VERSION ""

NS_ :

BS_:

BU_: ENERGY_METER INERTIAL_MEASUREMENT_UNIT SENSOR_CONTROL_UNIT VEHICLE_CONTROL_UNIT ACCUMULATOR_CONTROL_UNIT MOTOR_CONTROLLER EMUS_BMS U2C

BO_ 150 CAR_ERROR_STATE: 8 Vector__XXX
 SG_ error_state_multiplexor M : 0|8@1+ (1,0) [0|0] "" Vector__XXX
 SG_ car_error_2 m0 : 9|1@1+ (1,0) [0|0] "" Vector__XXX
 SG_ car_error_1 m0 : 8|1@1+ (1,0) [0|0] "" Vector__XXX

BO_ 782 Team_Data_2_Message: 8 Vector__XXX
 SG_ Team_Signal_4 : 39|32@0- (1,0) [-2147483648|2147483647] ""  ENERGY_METER
 SG_ Team_Signal_3 : 7|32@0- (1,0) [-2147483648|2147483647] ""  ENERGY_METER

BO_ 781 Team_Data_1_Message: 8 Vector__XXX
 SG_ Team_Signal_2 : 39|32@0- (1,0) [-2147483648|2147483647] ""  ENERGY_METER
 SG_ Team_Signal_1 : 7|32@0- (1,0) [-2147483648|2147483647] ""  ENERGY_METER

BO_ 2147486373 INV_Diag_Buffer: 8 MOTOR_CONTROLLER
 SG_ INV_Diag_Data_3 : 48|16@1- (1,0) [-32768|32767] "" Vector__XXX
 SG_ INV_Diag_Data_2 : 32|16@1- (1,0) [-32768|32767] "" Vector__XXX
 SG_ INV_Diag_Data_1 : 16|16@1- (1,0) [-32768|32767] "" Vector__XXX
 SG_ INV_Buffer_Segment : 8|8@1+ (1,0) [0|5] "" Vector__XXX
 SG_ INV_Buffer_Record : 0|8@1+ (1,0) [0|255] "" Vector__XXX

BO_ 613 BRAKE_TEMPS: 8 SENSOR_CONTROL_UNIT
 SG_ BackRightBrakeTemp : 48|16@1- (0.01,0) [-327.68|327.67] "degC" Vector__XXX
 SG_ BackLeftBrakeTemp : 32|16@1- (0.01,0) [-327.68|327.67] "degC" Vector__XXX
 SG_ FrontRightBrakeTemp : 16|16@1- (0.01,0) [-327.68|327.67] "degC" Vector__XXX
 SG_ FrontLeftBrakeTemp : 0|16@1- (0.01,0) [-327.68|327.67] "degC" Vector__XXX

BO_ 599 TWO_FOOT_RULE: 8 SENSOR_CONTROL_UNIT
 SG_ HTL_CH_ID_TWO_FOOT_RULE : 0|8@1+ (1,0) [0|1] "" Vector__XXX

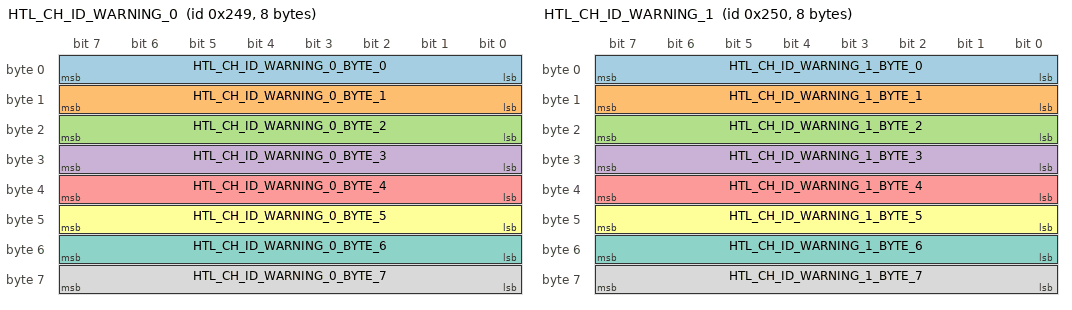
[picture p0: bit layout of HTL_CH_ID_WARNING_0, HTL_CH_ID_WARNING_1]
BO_ 585 HTL_CH_ID_WARNING_0: 8 SENSOR_CONTROL_UNIT
 SG_ HTL_CH_ID_WARNING_0_BYTE_0 : 0|8@1+ (1,0) [0|255] "" Vector__XXX
 SG_ HTL_CH_ID_WARNING_0_BYTE_1 : 8|8@1+ (1,0) [0|255] "" Vector__XXX
 SG_ HTL_CH_ID_WARNING_0_BYTE_2 : 16|8@1+ (1,0) [0|255] "" Vector__XXX
 SG_ HTL_CH_ID_WARNING_0_BYTE_3 : 24|8@1+ (1,0) [0|255] "" Vector__XXX
 SG_ HTL_CH_ID_WARNING_0_BYTE_4 : 32|8@1+ (1,0) [0|255] "" Vector__XXX
 SG_ HTL_CH_ID_WARNING_0_BYTE_5 : 40|8@1+ (1,0) [0|255] "" Vector__XXX
 SG_ HTL_CH_ID_WARNING_0_BYTE_6 : 48|8@1+ (1,0) [0|255] "" Vector__XXX
 SG_ HTL_CH_ID_WARNING_0_BYTE_7 : 56|8@1+ (1,0) [0|255] "" Vector__XXX

BO_ 592 HTL_CH_ID_WARNING_1: 8 SENSOR_CONTROL_UNIT
 SG_ HTL_CH_ID_WARNING_1_BYTE_0 : 0|8@1+ (1,0) [0|255] "" Vector__XXX
 SG_ HTL_CH_ID_WARNING_1_BYTE_1 : 8|8@1+ (1,0) [0|255] "" Vector__XXX
 SG_ HTL_CH_ID_WARNING_1_BYTE_2 : 16|8@1+ (1,0) [0|255] "" Vector__XXX
 SG_ HTL_CH_ID_WARNING_1_BYTE_3 : 24|8@1+ (1,0) [0|255] "" Vector__XXX
 SG_ HTL_CH_ID_WARNING_1_BYTE_4 : 32|8@1+ (1,0) [0|255] "" Vector__XXX
 SG_ HTL_CH_ID_WARNING_1_BYTE_5 : 40|8@1+ (1,0) [0|255] "" Vector__XXX
 SG_ HTL_CH_ID_WARNING_1_BYTE_6 : 48|8@1+ (1,0) [0|255] "" Vector__XXX
 SG_ HTL_CH_ID_WARNING_1_BYTE_7 : 56|8@1+ (1,0) [0|255] "" Vector__XXX

BO_ 544 HTL_CH_ID_APPS_TO_TORQUE_REQUEST: 8 SENSOR_CONTROL_UNIT
 SG_ HTL_CH_ID_APPS_TO_TORQUE_REQUEST : 0|16@1+ (0.1,0) [0|2400] "Nm" Vector__XXX

BO_ 537 HTL_CH_ID_BRAKE_PRESSED: 8 SENSOR_CONTROL_UNIT
 SG_ HTL_CH_ID_BRAKE_PRESSED : 0|8@1+ (1,0) [0|1] "" Vector__XXX

BO_ 536 HTL_CH_ID_APPS_PRESSED: 8 SENSOR_CONTROL_UNIT
 SG_ HTL_CH_ID_APPS_PRESSED : 0|8@1+ (1,0) [0|1] "" Vector__XXX

BO_ 535 HTL_CH_ID_SAFETY_LOOP_STATUS: 8 SENSOR_CONTROL_UNIT
 SG_ HTL_CH_ID_SAFETY_LOOP_STATUS : 0|8@1+ (1,0) [0|1] "" Vector__XXX

BO_ 1549 CAN_ENERGY_METER_TEMPERATURE: 8 ENERGY_METER
 SG_ Temp_31 m6 : 39|8@0+ (0.5,0) [0|127.5] "degC" Vector__XXX
 SG_ Temp_30 m6 : 31|8@0+ (0.5,0) [0|127.5] "degC" Vector__XXX
 SG_ Temp_29 m5 : 63|8@0+ (0.5,0) [0|127.5] "degC" Vector__XXX
 SG_ Temp_28 m5 : 55|8@0+ (0.5,0) [0|127.5] "degC" Vector__XXX
 SG_ Temp_27 m5 : 47|8@0+ (0.5,0) [0|127.5] "degC" Vector__XXX
 SG_ Temp_26 m5 : 39|8@0+ (0.5,0) [0|127.5] "degC" Vector__XXX
 SG_ Temp_25 m5 : 31|8@0+ (0.5,0) [0|127.5] "degC" Vector__XXX
 SG_ Temp_24 m4 : 63|8@0+ (0.5,0) [0|127.5] "degC" Vector__XXX
 SG_ Temp_23 m4 : 55|8@0+ (0.5,0) [0|127.5] "degC" Vector__XXX
 SG_ Temp_22 m4 : 47|8@0+ (0.5,0) [0|127.5] "degC" Vector__XXX
 SG_ Temp_21 m4 : 39|8@0+ (0.5,0) [0|127.5] "degC" Vector__XXX
 SG_ Temp_20 m4 : 31|8@0+ (0.5,0) [0|127.5] "degC" Vector__XXX
 SG_ Temp_19 m3 : 63|8@0+ (0.5,0) [0|127.5] "degC" Vector__XXX
 SG_ Temp_18 m3 : 55|8@0+ (0.5,0) [0|127.5] "degC" Vector__XXX
 SG_ Temp_17 m3 : 47|8@0+ (0.5,0) [0|127.5] "degC" Vector__XXX
 SG_ Temp_16 m3 : 39|8@0+ (0.5,0) [0|127.5] "degC" Vector__XXX
 SG_ Temp_15 m3 : 31|8@0+ (0.5,0) [0|127.5] "degC" Vector__XXX
 SG_ Temp_14 m2 : 63|8@0+ (0.5,0) [0|127.5] "degC" Vector__XXX
 SG_ Temp_13 m2 : 55|8@0+ (0.5,0) [0|127.5] "degC" Vector__XXX
 SG_ Temp_12 m2 : 47|8@0+ (0.5,0) [0|127.5] "degC" Vector__XXX
 SG_ Temp_11 m2 : 39|8@0+ (0.5,0) [0|127.5] "degC" Vector__XXX
 SG_ Temp_10 m2 : 31|8@0+ (0.5,0) [0|127.5] "degC" Vector__XXX
 SG_ Temp_9 m1 : 63|8@0+ (0.5,0) [0|127.5] "degC" Vector__XXX
 SG_ Temp_8 m1 : 55|8@0+ (0.5,0) [0|127.5] "degC" Vector__XXX
 SG_ Temp_7 m1 : 47|8@0+ (0.5,0) [0|127.5] "degC" Vector__XXX
 SG_ Temp_6 m1 : 39|8@0+ (0.5,0) [0|127.5] "degC" Vector__XXX
 SG_ Temp_5 m1 : 31|8@0+ (0.5,0) [0|127.5] "degC" Vector__XXX
 SG_ Temp_4 m0 : 63|8@0+ (0.5,0) [0|127.5] "degC" Vector__XXX
 SG_ Temp_3 m0 : 55|8@0+ (0.5,0) [0|127.5] "degC" Vector__XXX
 SG_ Temp_2 m0 : 47|8@0+ (0.5,0) [0|127.5] "degC" Vector__XXX
 SG_ Temp_1 m0 : 39|8@0+ (0.5,0) [0|127.5] "degC" Vector__XXX
 SG_ Temp_0 m0 : 31|8@0+ (0.5,0) [0|127.5] "degC" Vector__XXX
 SG_ Max_Temp : 23|8@0+ (0.5,0) [0|127.5] "degC" Vector__XXX
 SG_ Min_Temp : 15|8@0+ (0.5,0) [0|127.5] "degC" Vector__XXX
 SG_ Num_Sensors : 4|5@0+ (1,0) [0|31] "" Vector__XXX
 SG_ Temp_Multiplexor M : 7|3@0+ (1,0) [0|7] "" Vector__XXX

BO_ 1037 CAN_ENERGY_METER_STATUS: 5 ENERGY_METER
 SG_ EnergyMeterEnergy : 15|32@0- (1,0) [-3.4E+38|3.4E+38] "Whr" Vector__XXX
 SG_ EnergyMeterLogging : 1|1@0+ (1,0) [0|1] "" Vector__XXX
 SG_ EnergyMeterViolation : 0|1@0+ (1,0) [0|1] "" Vector__XXX

BO_ 269 CAN_ENERGY_METER_MEASUREMENT_MSG: 8 ENERGY_METER
 SG_ EnergyMeterVoltage : 39|32@0- (1,0) [-3.4E+38|3.4E+38] "V" Vector__XXX
 SG_ EnergyMeterCurrent : 7|32@0- (1,0) [-3.4E+38|3.4E+38] "A" Vector__XXX

BO_ 598 CAN_FLOW_METER: 2 SENSOR_CONTROL_UNIT
 SG_ FlowRate : 0|16@1+ (0.01,0) [0|655.35] "L/s" Vector__XXX

BO_ 597 CAN_COOLING_LOOP_TEMPERATURE: 8 SENSOR_CONTROL_UNIT
 SG_ TempSensor4 : 48|16@1- (0.01,0) [-327.68|327.67] "degC" Vector__XXX
 SG_ TempSensor3 : 32|16@1- (0.01,0) [-327.68|327.67] "degC" Vector__XXX
 SG_ TempSensor2 : 16|16@1- (0.01,0) [-327.68|327.67] "degC" Vector__XXX
 SG_ TempSensor1 : 0|16@1- (0.01,0) [-327.68|327.67] "degC" Vector__XXX

BO_ 596 CAN_SHOCK_POTENTIOMETERS: 8 SENSOR_CONTROL_UNIT
 SG_ BackRightShockPotentiometer : 48|16@1+ (0.01,0) [0|655.35] "mm" Vector__XXX
 SG_ BackLeftShockPotentiometer : 32|16@1+ (0.01,0) [0|655.35] "mm" Vector__XXX
 SG_ FrontRightShockPotentiometer : 16|16@1+ (0.01,0) [0|655.35] "mm" Vector__XXX
 SG_ FrontLeftShockPotentiometer : 0|16@1+ (0.01,0) [0|655.35] "mm" Vector__XXX

BO_ 595 CAN_LV_BATTERY_DATA: 8 SENSOR_CONTROL_UNIT
 SG_ LVBatteryPower : 48|16@1+ (0.01,0) [0|655.35] "W" Vector__XXX
 SG_ LVBatteryCurrent : 32|16@1- (0.01,0) [-327.68|327.67] "A" Vector__XXX
 SG_ LVBatteryVoltage : 16|16@1- (0.01,0) [-327.68|327.67] "V" Vector__XXX
 SG_ LVBatterySOC : 0|16@1+ (0.01,0) [0|655.35] "%" Vector__XXX

BO_ 594 CAN_WHEEL_SPEED: 8 SENSOR_CONTROL_UNIT
 SG_ BackRightWheelSpeed : 48|16@1- (0.01,0) [-327.68|327.67] "kph" Vector__XXX
 SG_ BackLeftWheelSpeed : 32|16@1- (0.01,0) [-327.68|327.67] "kph" Vector__XXX
 SG_ FrontLeftWheelSpeed : 16|16@1- (0.01,0) [-327.68|327.67] "kph" Vector__XXX
 SG_ FrontRightWheelSpeed : 0|16@1- (0.01,0) [-327.68|327.67] "kph" Vector__XXX

BO_ 593 CAN_VEHICLE_SPEED: 2 SENSOR_CONTROL_UNIT
 SG_ Vehicle_Speed : 0|16@1- (0.01,0) [-327.68|327.67] "kph" Vector__XXX

BO_ 2565876096 SlopeSensor_Type2: 8 INERTIAL_MEASUREMENT_UNIT
 SG_ PitchAngle : 7|16@0+ (0.0001526,0) [-3.1416|3.1416] "rad" Vector__XXX
 SG_ RollAngle : 23|16@0+ (0.0001526,0) [-3.1416|3.1416] "rad" Vector__XXX
 SG_ PitchAngleStatus : 55|2@0+ (1,0) [0|3] "" Vector__XXX
 SG_ RollAngleStatus : 53|2@0+ (1,0) [0|3] "" Vector__XXX

BO_ 2565876352 AngularRate: 8 INERTIAL_MEASUREMENT_UNIT
 SG_ PitchRate : 7|16@0+ (0.0078125,-250) [-250|250] "deg/s" Vector__XXX
 SG_ RollRate : 23|16@0+ (0.0078125,-250) [-250|250] "deg/s" Vector__XXX
 SG_ YawRate : 39|16@0+ (0.0078125,-250) [-250|250] "deg/s" Vector__XXX

BO_ 2565877120 Acceleration: 8 INERTIAL_MEASUREMENT_UNIT
 SG_ LongitudinalAccel : 7|16@0+ (0.01,-320) [-320|322.55] "m/s^2" Vector__XXX
 SG_ LateralAccel : 23|16@0+ (0.01,-320) [-320|322.55] "m/s^2" Vector__XXX
 SG_ VerticalAccel : 39|16@0+ (0.01,-320) [-320|322.55] "m/s^2" Vector__XXX

BO_ 2566875776 Magnetometer: 8 INERTIAL_MEASUREMENT_UNIT
 SG_ MagX : 7|16@0+ (0.001,-32) [-32|32] "Gauss" Vector__XXX
 SG_ MagY : 23|16@0+ (0.001,-32) [-32|32] "Gauss" Vector__XXX
 SG_ MagZ : 39|16@0+ (0.001,-32) [-32|32] "Gauss" Vector__XXX

BO_ 195 M195_Pedal_Press_Percent: 8 VEHICLE_CONTROL_UNIT
 SG_ Pedal_Press_Percent : 0|8@1+ (1,0) [0|255] "%" Vector__XXX

BO_ 194 M194_Read_Write_Param_Response: 8 MOTOR_CONTROLLER
 SG_ INV_Write_Success : 16|1@1+ (1,0) [0|1] "" Vector__XXX
 SG_ INV_Data_Response : 32|16@1- (1,0) [-32768|32767] "" Vector__XXX
 SG_ INV_Parameter_Address_Response : 0|16@1+ (1,0) [0|65535] "" Vector__XXX

BO_ 193 M193_Read_Write_Param_Command: 8 VEHICLE_CONTROL_UNIT
 SG_ VCU_INV_Data_Command : 32|16@1- (1,0) [-32768|32767] "" Vector__XXX
 SG_ VCU_INV_Read_Write_Command : 16|1@1+ (1,0) [0|1] "" Vector__XXX
 SG_ VCU_INV_Parameter_Address_Comman : 0|16@1+ (1,0) [0|65535] "" Vector__XXX

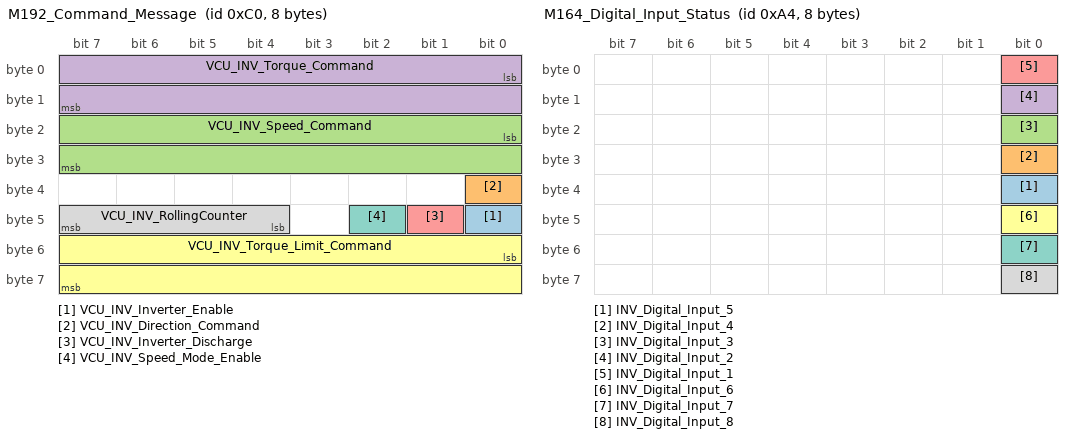
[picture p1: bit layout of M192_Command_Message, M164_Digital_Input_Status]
BO_ 192 M192_Command_Message: 8 VEHICLE_CONTROL_UNIT
 SG_ VCU_INV_Inverter_Enable : 40|1@1+ (1,0) [0|1] "Bit"  MOTOR_CONTROLLER
 SG_ VCU_INV_Direction_Command : 32|1@1+ (1,0) [0|1] "Bit"  MOTOR_CONTROLLER
 SG_ VCU_INV_Speed_Command : 16|16@1- (1,0) [-32768|32767] "rpm"  MOTOR_CONTROLLER
 SG_ VCU_INV_Torque_Command : 0|16@1- (0.1,0) [-3276.8|3276.7] "torque:N.m"  MOTOR_CONTROLLER
 SG_ VCU_INV_Inverter_Discharge : 41|1@1+ (1,0) [0|1] ""  MOTOR_CONTROLLER
 SG_ VCU_INV_Torque_Limit_Command : 48|16@1- (0.1,0) [-3276.8|3276.7] "torque:N.m"  MOTOR_CONTROLLER
 SG_ VCU_INV_Speed_Mode_Enable : 42|1@1+ (1,0) [0|1] ""  MOTOR_CONTROLLER
 SG_ VCU_INV_RollingCounter : 44|4@1+ (1,0) [0|15] ""  MOTOR_CONTROLLER

BO_ 177 CAN_MC_RX_TORQUE_CAPABILITY: 8 MOTOR_CONTROLLER

BO_ 176 M176_Fast_Info: 8 MOTOR_CONTROLLER
 SG_ INV_Fast_Torque_Command : 0|16@1- (0.1,0) [-3276.8|3276.7] "torque:N.m" Vector__XXX
 SG_ INV_Fast_Torque_Feedback : 16|16@1- (0.1,0) [-3276.8|3276.7] "torque:N.m" Vector__XXX
 SG_ INV_Fast_Motor_Speed : 32|16@1- (1,0) [-32768|32767] "angular_speed:rpm" Vector__XXX
 SG_ INV_Fast_DC_Bus_Voltage : 48|16@1- (0.1,0) [-3276.8|3276.7] "voltage:V" Vector__XXX

BO_ 175 M175_Diag_Data_Message: 8 MOTOR_CONTROLLER
 SG_ INV_Diag_Record : 0|8@1+ (1,0) [0|160] "" Vector__XXX
 SG_ INV_Diag_Segment M : 8|8@1+ (1,0) [0|5] "" Vector__XXX
 SG_ INV_Diag_Gamma_Resolver m0 : 16|16@1- (0.1,0) [0|360] "angle:deg" Vector__XXX
 SG_ INV_Diag_Gamma_Observer m0 : 32|16@1- (0.1,0) [0|360] "angle:deg" Vector__XXX
 SG_ INV_Diag_Sin m0 : 48|16@1- (1,0) [-5|5] "voltage:V" Vector__XXX
 SG_ INV_Diag_Cos m1 : 16|16@1- (1,0) [-5|5] "voltage:V" Vector__XXX
 SG_ INV_Diag_Ia m1 : 32|16@1- (0.1,0) [-2000|2000] "current:A" Vector__XXX
 SG_ INV_Diag_Ib m1 : 48|16@1- (0.1,0) [-2000|2000] "current:A" Vector__XXX
 SG_ INV_Diag_Ic m2 : 16|16@1- (0.1,0) [-2000|2000] "current:A" Vector__XXX
 SG_ INV_Diag_Vdc m2 : 32|16@1- (0.1,0) [0|1000] "voltage:V" Vector__XXX
 SG_ INV_Diag_Iq_cmd m2 : 48|16@1- (0.1,0) [-2000|2000] "current:A" Vector__XXX
 SG_ INV_Diag_Id_cmd m3 : 16|16@1- (0.1,0) [-2000|2000] "current:A" Vector__XXX
 SG_ INV_Diag_Mod_Index m3 : 32|16@1- (0.0001,0) [0|2] "" Vector__XXX
 SG_ INV_Diag_FW_Output m3 : 48|16@1- (0.1,0) [-2000|2000] "current:A" Vector__XXX
 SG_ INV_Diag_Vq_Cmd m4 : 16|16@1- (0.1,0) [-1000|1000] "voltage:V" Vector__XXX
 SG_ INV_Diag_Vd_Cmd m4 : 32|16@1- (0.1,0) [-1000|1000] "voltage:V" Vector__XXX
 SG_ INV_Diag_Vqs_Cmd m4 : 48|16@1- (0.1,0) [-1000|1000] "voltage:V" Vector__XXX
 SG_ INV_Diag_12V m5 : 16|16@1+ (0.01,0) [0|36] "voltage:V" Vector__XXX
 SG_ INV_Diag_Run_Faults_Lo m5 : 32|16@1+ (1,0) [0|65535] "" Vector__XXX
 SG_ INV_Diag_Run_Faults_Hi m5 : 48|16@1+ (1,0) [0|65535] "" Vector__XXX

BO_ 174 M174_Firmware_Info: 8 MOTOR_CONTROLLER
 SG_ INV_Project_Code_EEP_Ver : 0|16@1+ (1,0) [0|65535] "" Vector__XXX
 SG_ INV_SW_Version : 16|16@1+ (1,0) [0|65535] "" Vector__XXX
 SG_ INV_DateCode_MMDD : 32|16@1+ (1,0) [0|65535] "" Vector__XXX
 SG_ INV_DateCode_YYYY : 48|16@1+ (1,0) [0|65535] "" Vector__XXX

BO_ 173 M173_Modulation_And_Flux_Info: 8 MOTOR_CONTROLLER
 SG_ INV_Iq_Command : 48|16@1- (0.1,0) [-3276.8|3276.7] "current:A" Vector__XXX
 SG_ INV_Id_Command : 32|16@1- (0.1,0) [-3276.8|3276.7] "current:A" Vector__XXX
 SG_ INV_Flux_Weakening_Output : 16|16@1- (0.1,0) [-3276.8|3276.7] "current:A" Vector__XXX
 SG_ INV_Modulation_Index : 0|16@1- (0.0001,0) [0|3.2767] "" Vector__XXX

BO_ 172 M172_Torque_And_Timer_Info: 8 MOTOR_CONTROLLER
 SG_ INV_Power_On_Timer : 32|32@1+ (0.003,0) [0|12884800] "time:sec" Vector__XXX
 SG_ INV_Torque_Feedback : 16|16@1- (0.1,0) [-3276.8|3276.7] "torque:N.m" Vector__XXX
 SG_ INV_Commanded_Torque : 0|16@1- (0.1,0) [-3276.8|3276.7] "torque:N.m" Vector__XXX

BO_ 171 M171_Fault_Codes: 8 MOTOR_CONTROLLER
 SG_ INV_Run_Fault_Hi : 48|16@1+ (1,0) [0|65535] "" Vector__XXX
 SG_ INV_Post_Fault_Hi : 16|16@1+ (1,0) [0|65535] "" Vector__XXX
 SG_ INV_Run_Fault_Lo : 32|16@1+ (1,0) [0|65535] "" Vector__XXX
 SG_ INV_Post_Fault_Lo : 0|16@1+ (1,0) [0|65535] "" Vector__XXX

BO_ 170 M170_Internal_States: 8 MOTOR_CONTROLLER
 SG_ INV_Direction_Command : 56|1@1+ (1,0) [0|1] "" Vector__XXX
 SG_ INV_Inverter_Enable_State : 48|1@1+ (1,0) [0|1] "" Vector__XXX
 SG_ INV_Relay_3_Status : 26|1@1+ (1,0) [0|1] "" Vector__XXX
 SG_ INV_Relay_4_Status : 27|1@1+ (1,0) [0|1] "" Vector__XXX
 SG_ INV_Relay_2_Status : 25|1@1+ (1,0) [0|1] "" Vector__XXX
 SG_ INV_Inverter_Run_Mode : 32|1@1+ (1,0) [0|1] "" Vector__XXX
 SG_ INV_Inverter_Command_Mode : 40|1@1+ (1,0) [0|1] "" Vector__XXX
 SG_ INV_Relay_1_Status : 24|1@1+ (1,0) [0|1] "" Vector__XXX
 SG_ INV_Inverter_State : 16|8@1+ (1,0) [0|255] "" Vector__XXX
 SG_ INV_VSM_State : 0|8@1+ (1,0) [0|15] "" Vector__XXX
 SG_ INV_Inverter_Enable_Lockout : 55|1@1+ (1,0) [0|1] "" Vector__XXX
 SG_ INV_Inverter_Discharge_State : 37|3@1+ (1,0) [0|7] "" Vector__XXX
 SG_ INV_Relay_5_Status : 28|1@1+ (1,0) [0|1] "" Vector__XXX
 SG_ INV_Relay_6_Status : 29|1@1+ (1,0) [0|1] "" Vector__XXX
 SG_ INV_BMS_Active : 57|1@1+ (1,0) [0|1] "" Vector__XXX
 SG_ INV_BMS_Torque_Limiting : 58|1@1+ (1,0) [0|1] "" Vector__XXX
 SG_ INV_Max_Speed_Limiting : 59|1@1+ (1,0) [0|1] "" Vector__XXX
 SG_ INV_Low_Speed_Limiting : 61|1@1+ (1,0) [0|1] "" Vector__XXX
 SG_ INV_Rolling_Counter : 44|4@1+ (1,0) [0|15] "" Vector__XXX
 SG_ INV_PWM_Frequency : 8|8@1+ (1,0) [0|255] "kHz" Vector__XXX
 SG_ INV_Start_Mode_Active : 54|1@1+ (1,0) [0|1] "" Vector__XXX

BO_ 169 M169_Internal_Voltages: 8 MOTOR_CONTROLLER
 SG_ INV_Reference_Voltage_12_0 : 48|16@1- (0.01,0) [-327.68|327.67] "voltage:V" Vector__XXX
 SG_ INV_Reference_Voltage_5_0 : 32|16@1- (0.01,0) [-327.68|327.67] "voltage:V" Vector__XXX
 SG_ INV_Reference_Voltage_2_5 : 16|16@1- (0.01,0) [-327.68|327.67] "voltage:V" Vector__XXX
 SG_ INV_Reference_Voltage_1_5 : 0|16@1- (0.01,0) [-327.68|327.67] "voltage:V" Vector__XXX

BO_ 168 M168_Flux_ID_IQ_Info: 8 MOTOR_CONTROLLER
 SG_ INV_Iq : 48|16@1- (0.1,0) [-3276.8|3276.7] "current:A" Vector__XXX
 SG_ INV_Id : 32|16@1- (0.1,0) [-3276.8|3276.7] "current:A" Vector__XXX
 SG_ INV_Flux_Feedback : 16|16@1- (0.001,0) [-32.768|32.767] "flux:Wb" Vector__XXX
 SG_ INV_Flux_Command : 0|16@1- (0.001,0) [-32.768|32.767] "flux:Wb" Vector__XXX

BO_ 167 M167_Voltage_Info: 8 MOTOR_CONTROLLER
 SG_ INV_VBC_Vq_Voltage : 48|16@1- (0.1,0) [-3276.8|3276.7] "voltage:V" Vector__XXX
 SG_ INV_VAB_Vd_Voltage : 32|16@1- (0.1,0) [-3276.8|3276.7] "voltage:V" Vector__XXX
 SG_ INV_Output_Voltage : 16|16@1- (0.1,0) [-3276.8|3276.7] "voltage:V" Vector__XXX
 SG_ INV_DC_Bus_Voltage : 0|16@1- (0.1,0) [-3276.8|3276.7] "voltage:V" Vector__XXX

BO_ 166 M166_Current_Info: 8 MOTOR_CONTROLLER
 SG_ INV_DC_Bus_Current : 48|16@1- (0.1,0) [-3276.8|3276.7] "current:A" Vector__XXX
 SG_ INV_Phase_C_Current : 32|16@1- (0.1,0) [-3276.8|3276.7] "current:A" Vector__XXX
 SG_ INV_Phase_B_Current : 16|16@1- (0.1,0) [-3276.8|3276.7] "current:A" Vector__XXX
 SG_ INV_Phase_A_Current : 0|16@1- (0.1,0) [-3276.8|3276.7] "current:A" Vector__XXX

BO_ 165 M165_Motor_Position_Info: 8 MOTOR_CONTROLLER
 SG_ INV_Delta_Resolver_Filtered : 48|16@1- (0.1,0) [-3276.8|3276.7] "angle:deg" Vector__XXX
 SG_ INV_Electrical_Output_Frequency : 32|16@1- (0.1,0) [-3276.8|3276.7] "frequency:Hz" Vector__XXX
 SG_ INV_Motor_Speed : 16|16@1- (1,0) [-32768|32767] "angular_speed:rpm" Vector__XXX
 SG_ INV_Motor_Angle_Electrical : 0|16@1+ (0.1,0) [0|6553.5] "angle:deg" Vector__XXX

BO_ 164 M164_Digital_Input_Status: 8 MOTOR_CONTROLLER
 SG_ INV_Digital_Input_5 : 32|1@1+ (1,0) [0|1] "" Vector__XXX
 SG_ INV_Digital_Input_4 : 24|1@1+ (1,0) [0|1] "" Vector__XXX
 SG_ INV_Digital_Input_3 : 16|1@1+ (1,0) [0|1] "" Vector__XXX
 SG_ INV_Digital_Input_2 : 8|1@1+ (1,0) [0|1] "" Vector__XXX
 SG_ INV_Digital_Input_1 : 0|1@1+ (1,0) [0|1] "" Vector__XXX
 SG_ INV_Digital_Input_6 : 40|1@1+ (1,0) [0|1] "" Vector__XXX
 SG_ INV_Digital_Input_7 : 48|1@1+ (1,0) [0|1] "" Vector__XXX
 SG_ INV_Digital_Input_8 : 56|1@1+ (1,0) [0|1] "" Vector__XXX

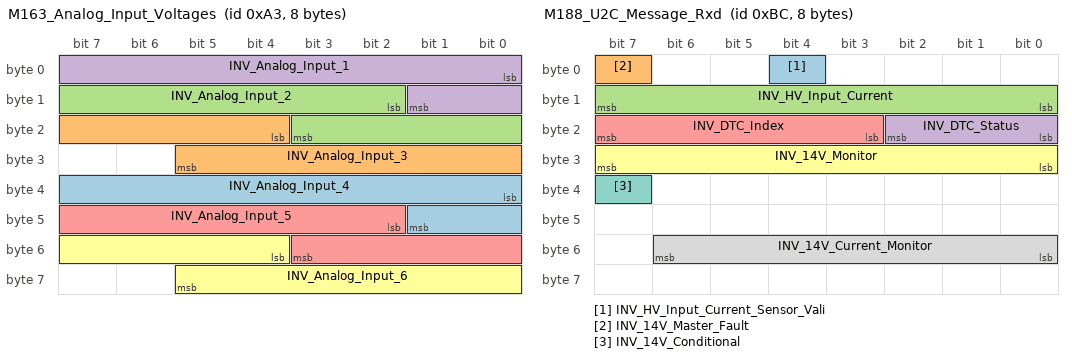
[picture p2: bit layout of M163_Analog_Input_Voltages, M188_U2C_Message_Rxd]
BO_ 163 M163_Analog_Input_Voltages: 8 MOTOR_CONTROLLER
 SG_ INV_Analog_Input_4 : 32|10@1+ (0.01,0) [0|10.23] "voltage:V" Vector__XXX
 SG_ INV_Analog_Input_3 : 20|10@1+ (0.01,0) [0|10.23] "voltage:V" Vector__XXX
 SG_ INV_Analog_Input_2 : 10|10@1+ (0.01,0) [0|10.23] "voltage:V" Vector__XXX
 SG_ INV_Analog_Input_1 : 0|10@1+ (0.01,0) [0|10.23] "voltage:V" Vector__XXX
 SG_ INV_Analog_Input_5 : 42|10@1+ (0.01,0) [0|10.23] "voltage:V" Vector__XXX
 SG_ INV_Analog_Input_6 : 52|10@1+ (0.01,0) [0|10.23] "voltage:V" Vector__XXX

BO_ 162 M162_Temperature_Set_3: 8 MOTOR_CONTROLLER
 SG_ INV_Torque_Shudder : 48|16@1- (0.1,0) [-3276.8|3276.7] "torque:N.m" Vector__XXX
 SG_ INV_Motor_Temperature : 32|16@1- (0.1,0) [-3276.8|3276.7] "temperature:C" Vector__XXX
 SG_ INV_RTD5_Temperature : 16|16@1- (0.1,0) [-3276.8|3276.7] "temperature:C" Vector__XXX
 SG_ INV_RTD4_Temperature : 0|16@1- (0.1,0) [-3276.8|3276.7] "temperature:C" Vector__XXX

BO_ 161 M161_Temperature_Set_2: 8 MOTOR_CONTROLLER
 SG_ INV_RTD3_Temperature : 48|16@1- (0.1,0) [-3276.8|3276.7] "temperature:C" Vector__XXX
 SG_ INV_RTD2_Temperature : 32|16@1- (0.1,0) [-3276.8|3276.7] "temperature:C" Vector__XXX
 SG_ INV_RTD1_Temperature : 16|16@1- (0.1,0) [-3276.8|3276.7] "temperature:C" Vector__XXX
 SG_ INV_Control_Board_Temperature : 0|16@1- (0.1,0) [-3276.8|3276.7] "temperature:C" Vector__XXX

BO_ 160 M160_Temperature_Set_1: 8 MOTOR_CONTROLLER
 SG_ INV_Gate_Driver_Board : 48|16@1- (0.1,0) [-3276.8|3276.7] "temperature:C" Vector__XXX
 SG_ INV_Module_C : 32|16@1- (0.1,0) [-3276.8|3276.7] "temperature:C" Vector__XXX
 SG_ INV_Module_B : 16|16@1- (0.1,0) [-3276.8|3276.7] "temperature:C" Vector__XXX
 SG_ INV_Module_A : 0|16@1- (0.1,0) [-3276.8|3276.7] "temperature:C" Vector__XXX

BO_ 471 M187_U2C_Command_Txd: 8 MOTOR_CONTROLLER
 SG_ U2C_ID_Byte : 0|8@1+ (1,0) [0|255] "" Vector__XXX
 SG_ U2C_Setpoint_Calc : 8|8@1+ (1,0) [0|255] "" Vector__XXX

BO_ 514 BMS_Current_Limit: 8 EMUS_BMS
 SG_ INV_Max_Discharge_Current : 0|16@1+ (1,0) [0|1000] "current:A" Vector__XXX
 SG_ INV_Max_Charge_Current : 16|16@1+ (1,0) [0|1000] "current:A" Vector__XXX

BO_ 188 M188_U2C_Message_Rxd: 8 U2C
 SG_ INV_HV_Input_Current_Sensor_Vali : 4|1@1+ (1,0) [0|1] "" Vector__XXX
 SG_ INV_14V_Master_Fault : 7|1@1+ (1,0) [0|1] "" Vector__XXX
 SG_ INV_HV_Input_Current : 8|8@1+ (1,0) [0|255] "" Vector__XXX
 SG_ INV_DTC_Status : 16|3@1+ (1,0) [0|7] "" Vector__XXX
 SG_ INV_DTC_Index : 19|5@1+ (1,0) [0|31] "" Vector__XXX
 SG_ INV_14V_Monitor : 24|8@1+ (1,0) [0|255] "" Vector__XXX
 SG_ INV_14V_Conditional : 39|1@1+ (1,0) [0|1] "" Vector__XXX
 SG_ INV_14V_Current_Monitor : 48|7@1+ (1,0) [0|127] "" Vector__XXX

BO_ 573 Charger_Control_Std: 1 Vector__XXX
 SG_ Charger_Control : 7|8@0- (1,0) [0|2] "" Vector__XXX

BO_ 2578777096 Charger_Control_Ext: 1 Vector__XXX
 SG_ Charger_Control : 7|8@0- (1,0) [0|2] "" Vector__XXX

BO_ 453 State_Of_Charge_Health_Param_Std: 8 Vector__XXX
 SG_ SOCSOHParams_USER_SOC : 39|16@0+ (0.01,0) [0|655.35] "%" Vector__XXX
 SG_ SOCSOHParams_SOH : 55|16@0+ (0.01,0) [0|655.35] "%" Vector__XXX
 SG_ SOCSOHParams_SOC : 23|16@0+ (0.01,0) [0|655.35] "%" Vector__XXX

BO_ 2578776080 State_Of_Charge_Health_Param_Ext: 8 Vector__XXX
 SG_ SOCSOHParams_USER_SOC : 39|16@0+ (0.01,0) [0|655.35] "%" Vector__XXX
 SG_ SOCSOHParams_SOH : 55|16@0+ (0.01,0) [0|655.35] "%" Vector__XXX
 SG_ SOCSOHParams_SOC : 23|16@0+ (0.01,0) [0|655.35] "%" Vector__XXX

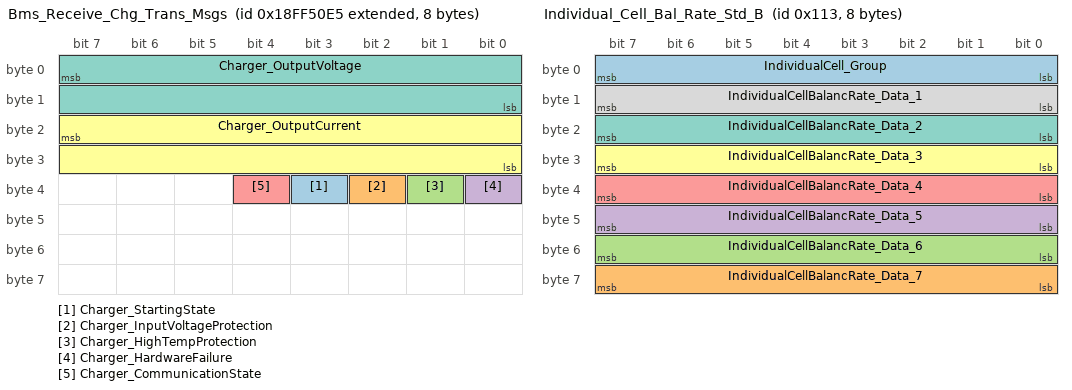
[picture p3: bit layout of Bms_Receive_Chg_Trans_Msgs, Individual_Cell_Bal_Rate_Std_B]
BO_ 2566869221 Bms_Receive_Chg_Trans_Msgs: 8 Vector__XXX
 SG_ Charger_StartingState : 35|1@0+ (1,0) [0|1] ""  EMUS_BMS
 SG_ Charger_InputVoltageProtection : 34|1@0+ (1,0) [0|1] ""  EMUS_BMS
 SG_ Charger_HighTempProtection : 33|1@0+ (1,0) [0|1] ""  EMUS_BMS
 SG_ Charger_HardwareFailure : 32|1@0+ (1,0) [0|1] ""  EMUS_BMS
 SG_ Charger_CommunicationState : 36|1@0+ (1,0) [0|1] ""  EMUS_BMS
 SG_ Charger_OutputCurrent : 23|16@0+ (0.1,0) [0|65535.01] "A"  EMUS_BMS
 SG_ Charger_OutputVoltage : 7|16@0+ (0.1,0) [0|65535.01] "V"  EMUS_BMS

BO_ 2550588916 Bms_Transmits_Cgh_Receive_Msgs: 8 EMUS_BMS
 SG_ Bms_MaxAllowedChrgVolt : 7|16@0+ (0.1,0) [0|65535.01] "V" Vector__XXX
 SG_ Bms_MaxAllowedChrgCurr : 23|16@0+ (0.1,0) [0|65535.01] "A" Vector__XXX
 SG_ Bms_Control : 39|8@0+ (1,0) [0|1] "" Vector__XXX

BO_ 275 Individual_Cell_Bal_Rate_Std_B: 8 EMUS_BMS
 SG_ IndividualCell_Group : 7|8@0+ (1,0) [0|255] "" Vector__XXX
 SG_ IndividualCellBalancRate_Data_7 : 63|8@0+ (0.392156862745098,0) [0|100] "%" Vector__XXX
 SG_ IndividualCellBalancRate_Data_6 : 55|8@0+ (0.392156862745098,0) [0|100] "%" Vector__XXX
 SG_ IndividualCellBalancRate_Data_5 : 47|8@0+ (0.392156862745098,0) [0|100] "%" Vector__XXX
 SG_ IndividualCellBalancRate_Data_4 : 39|8@0+ (0.392156862745098,0) [0|100] "%" Vector__XXX
 SG_ IndividualCellBalancRate_Data_3 : 31|8@0+ (0.392156862745098,0) [0|100] "%" Vector__XXX
 SG_ IndividualCellBalancRate_Data_2 : 23|8@0+ (0.392156862745098,0) [0|100] "%" Vector__XXX
 SG_ IndividualCellBalancRate_Data_1 : 15|8@0+ (0.392156862745098,0) [0|100] "%" Vector__XXX

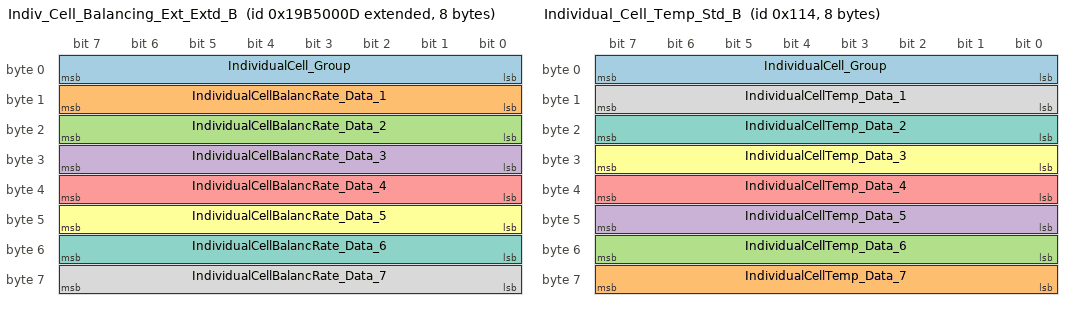
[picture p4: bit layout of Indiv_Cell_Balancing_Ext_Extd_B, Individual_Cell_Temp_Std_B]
BO_ 2578776077 Indiv_Cell_Balancing_Ext_Extd_B: 8 Vector__XXX
 SG_ IndividualCell_Group : 7|8@0+ (1,0) [0|255] "" Vector__XXX
 SG_ IndividualCellBalancRate_Data_1 : 15|8@0+ (0.392156862745098,0) [0|100] "%" Vector__XXX
 SG_ IndividualCellBalancRate_Data_2 : 23|8@0+ (0.392156862745098,0) [0|100] "%" Vector__XXX
 SG_ IndividualCellBalancRate_Data_3 : 31|8@0+ (0.392156862745098,0) [0|100] "%" Vector__XXX
 SG_ IndividualCellBalancRate_Data_4 : 39|8@0+ (0.392156862745098,0) [0|100] "%" Vector__XXX
 SG_ IndividualCellBalancRate_Data_5 : 47|8@0+ (0.392156862745098,0) [0|100] "%" Vector__XXX
 SG_ IndividualCellBalancRate_Data_6 : 55|8@0+ (0.392156862745098,0) [0|100] "%" Vector__XXX
 SG_ IndividualCellBalancRate_Data_7 : 63|8@0+ (0.392156862745098,0) [0|100] "%" Vector__XXX

BO_ 276 Individual_Cell_Temp_Std_B: 8 EMUS_BMS
 SG_ IndividualCell_Group : 7|8@0+ (1,0) [0|255] "" Vector__XXX
 SG_ IndividualCellTemp_Data_7 : 63|8@0+ (1,-100) [-100|155] "C" Vector__XXX
 SG_ IndividualCellTemp_Data_6 : 55|8@0+ (1,-100) [-100|155] "C" Vector__XXX
 SG_ IndividualCellTemp_Data_5 : 47|8@0+ (1,-100) [-100|155] "C" Vector__XXX
 SG_ IndividualCellTemp_Data_4 : 39|8@0+ (1,-100) [-100|155] "C" Vector__XXX
 SG_ IndividualCellTemp_Data_3 : 31|8@0+ (1,-100) [-100|155] "C" Vector__XXX
 SG_ IndividualCellTemp_Data_2 : 23|8@0+ (1,-100) [-100|155] "C" Vector__XXX
 SG_ IndividualCellTemp_Data_1 : 15|8@0+ (1,-100) [-100|155] "C" Vector__XXX

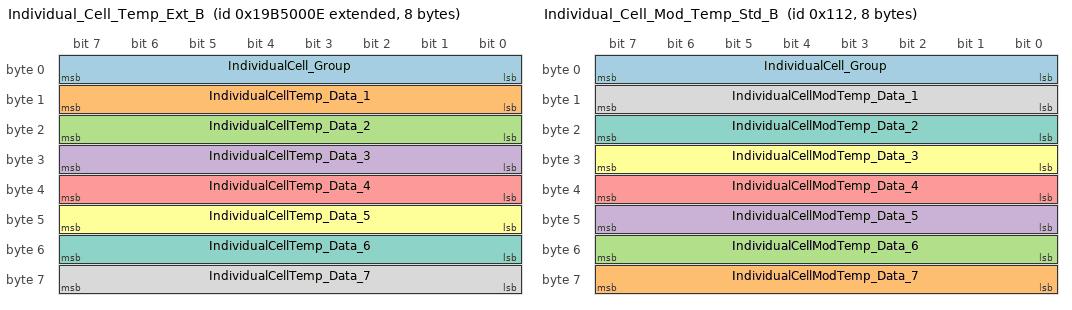
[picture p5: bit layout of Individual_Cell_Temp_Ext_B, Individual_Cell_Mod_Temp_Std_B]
BO_ 2578776078 Individual_Cell_Temp_Ext_B: 8 Vector__XXX
 SG_ IndividualCell_Group : 7|8@0+ (1,0) [0|255] "" Vector__XXX
 SG_ IndividualCellTemp_Data_1 : 15|8@0+ (1,-100) [-100|155] "C" Vector__XXX
 SG_ IndividualCellTemp_Data_2 : 23|8@0+ (1,-100) [-100|155] "C" Vector__XXX
 SG_ IndividualCellTemp_Data_3 : 31|8@0+ (1,-100) [-100|155] "C" Vector__XXX
 SG_ IndividualCellTemp_Data_4 : 39|8@0+ (1,-100) [-100|155] "C" Vector__XXX
 SG_ IndividualCellTemp_Data_5 : 47|8@0+ (1,-100) [-100|155] "C" Vector__XXX
 SG_ IndividualCellTemp_Data_6 : 55|8@0+ (1,-100) [-100|155] "C" Vector__XXX
 SG_ IndividualCellTemp_Data_7 : 63|8@0+ (1,-100) [-100|155] "C" Vector__XXX

BO_ 274 Individual_Cell_Mod_Temp_Std_B: 8 EMUS_BMS
 SG_ IndividualCell_Group : 7|8@0+ (1,0) [0|255] "" Vector__XXX
 SG_ IndividualCellModTemp_Data_7 : 63|8@0+ (1,-100) [-100|155] "C" Vector__XXX
 SG_ IndividualCellModTemp_Data_6 : 55|8@0+ (1,-100) [-100|155] "C" Vector__XXX
 SG_ IndividualCellModTemp_Data_5 : 47|8@0+ (1,-100) [-100|155] "C" Vector__XXX
 SG_ IndividualCellModTemp_Data_4 : 39|8@0+ (1,-100) [-100|155] "C" Vector__XXX
 SG_ IndividualCellModTemp_Data_3 : 31|8@0+ (1,-100) [-100|155] "C" Vector__XXX
 SG_ IndividualCellModTemp_Data_2 : 23|8@0+ (1,-100) [-100|155] "C" Vector__XXX
 SG_ IndividualCellModTemp_Data_1 : 15|8@0+ (1,-100) [-100|155] "C" Vector__XXX

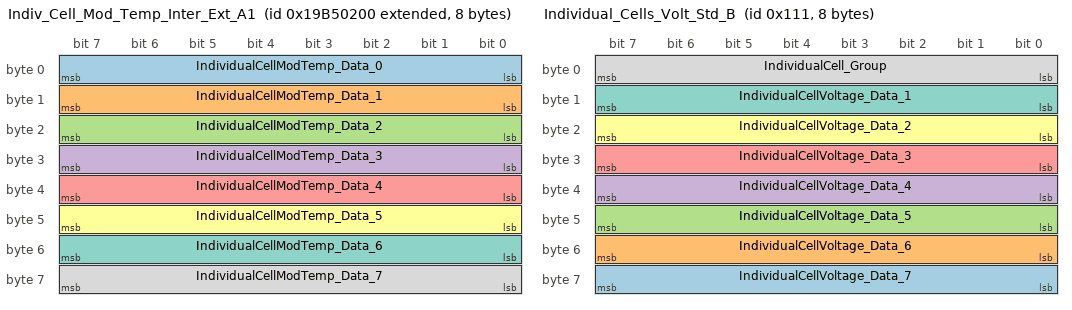
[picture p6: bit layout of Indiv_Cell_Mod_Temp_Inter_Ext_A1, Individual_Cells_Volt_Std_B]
BO_ 2578776576 Indiv_Cell_Mod_Temp_Inter_Ext_A1: 8 Vector__XXX
 SG_ IndividualCellModTemp_Data_0 : 7|8@0+ (1,-100) [-100|155] "C" Vector__XXX
 SG_ IndividualCellModTemp_Data_1 : 15|8@0+ (1,-100) [-100|155] "C" Vector__XXX
 SG_ IndividualCellModTemp_Data_2 : 23|8@0+ (1,-100) [-100|155] "C" Vector__XXX
 SG_ IndividualCellModTemp_Data_3 : 31|8@0+ (1,-100) [-100|155] "C" Vector__XXX
 SG_ IndividualCellModTemp_Data_4 : 39|8@0+ (1,-100) [-100|155] "C" Vector__XXX
 SG_ IndividualCellModTemp_Data_5 : 47|8@0+ (1,-100) [-100|155] "C" Vector__XXX
 SG_ IndividualCellModTemp_Data_6 : 55|8@0+ (1,-100) [-100|155] "C" Vector__XXX
 SG_ IndividualCellModTemp_Data_7 : 63|8@0+ (1,-100) [-100|155] "C" Vector__XXX

BO_ 273 Individual_Cells_Volt_Std_B: 8 EMUS_BMS
 SG_ IndividualCellVoltage_Data_7 : 63|8@0+ (0.01,2) [2|4.55] "V" Vector__XXX
 SG_ IndividualCellVoltage_Data_6 : 55|8@0+ (0.01,2) [2|4.55] "V" Vector__XXX
 SG_ IndividualCellVoltage_Data_5 : 47|8@0+ (0.01,2) [2|4.55] "V" Vector__XXX
 SG_ IndividualCellVoltage_Data_4 : 39|8@0+ (0.01,2) [2|4.55] "V" Vector__XXX
 SG_ IndividualCellVoltage_Data_3 : 31|8@0+ (0.01,2) [2|4.55] "V" Vector__XXX
 SG_ IndividualCellVoltage_Data_2 : 23|8@0+ (0.01,2) [2|4.55] "V" Vector__XXX
 SG_ IndividualCellVoltage_Data_1 : 15|8@0+ (0.01,2) [2|4.55] "V" Vector__XXX
 SG_ IndividualCell_Group : 7|8@0+ (1,0) [0|255] "" Vector__XXX

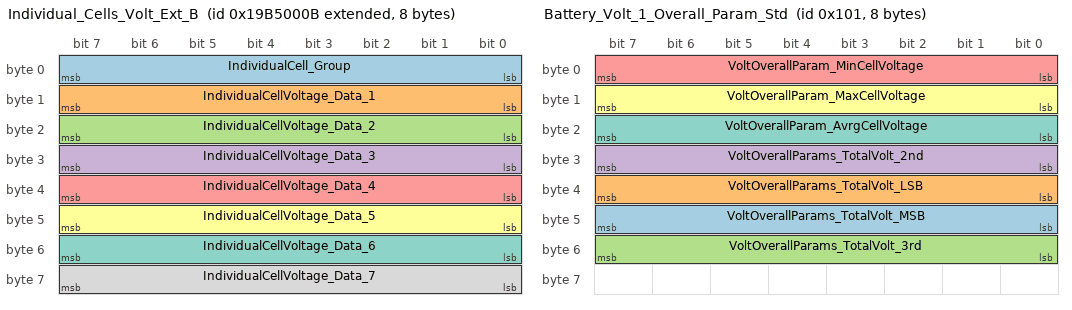
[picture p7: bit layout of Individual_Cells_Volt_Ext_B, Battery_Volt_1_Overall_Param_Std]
BO_ 2578776075 Individual_Cells_Volt_Ext_B: 8 Vector__XXX
 SG_ IndividualCell_Group : 7|8@0+ (1,0) [0|255] "" Vector__XXX
 SG_ IndividualCellVoltage_Data_1 : 15|8@0+ (0.01,2) [2|4.55] "V" Vector__XXX
 SG_ IndividualCellVoltage_Data_2 : 23|8@0+ (0.01,2) [2|4.55] "V" Vector__XXX
 SG_ IndividualCellVoltage_Data_3 : 31|8@0+ (0.01,2) [2|4.55] "V" Vector__XXX
 SG_ IndividualCellVoltage_Data_4 : 39|8@0+ (0.01,2) [2|4.55] "V" Vector__XXX
 SG_ IndividualCellVoltage_Data_5 : 47|8@0+ (0.01,2) [2|4.55] "V" Vector__XXX
 SG_ IndividualCellVoltage_Data_6 : 55|8@0+ (0.01,2) [2|4.55] "V" Vector__XXX
 SG_ IndividualCellVoltage_Data_7 : 63|8@0+ (0.01,2) [2|4.55] "V" Vector__XXX

BO_ 257 Battery_Volt_1_Overall_Param_Std: 8 EMUS_BMS
 SG_ VoltOverallParams_TotalVolt_MSB : 47|8@0+ (1,0) [0|255] "" Vector__XXX
 SG_ VoltOverallParams_TotalVolt_LSB : 39|8@0+ (1,0) [0|255] "" Vector__XXX
 SG_ VoltOverallParams_TotalVolt_3rd : 55|8@0+ (1,0) [0|255] "" Vector__XXX
 SG_ VoltOverallParams_TotalVolt_2nd : 31|8@0+ (1,0) [0|255] "" Vector__XXX
 SG_ VoltOverallParam_MinCellVoltage : 7|8@0+ (0.01,2) [2|4.55] "V" Vector__XXX
 SG_ VoltOverallParam_MaxCellVoltage : 15|8@0+ (0.01,2) [2|4.55] "V" Vector__XXX
 SG_ VoltOverallParam_AvrgCellVoltage : 23|8@0+ (0.01,2) [2|4.55] "V" Vector__XXX

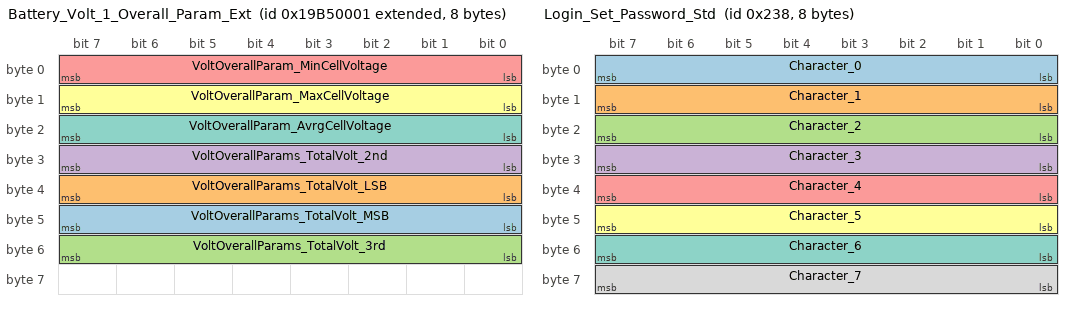
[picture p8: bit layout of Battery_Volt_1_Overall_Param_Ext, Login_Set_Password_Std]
BO_ 2578776065 Battery_Volt_1_Overall_Param_Ext: 8 EMUS_BMS
 SG_ VoltOverallParams_TotalVolt_MSB : 47|8@0+ (1,0) [0|255] "" Vector__XXX
 SG_ VoltOverallParams_TotalVolt_LSB : 39|8@0+ (1,0) [0|255] "" Vector__XXX
 SG_ VoltOverallParams_TotalVolt_3rd : 55|8@0+ (1,0) [0|255] "" Vector__XXX
 SG_ VoltOverallParams_TotalVolt_2nd : 31|8@0+ (1,0) [0|2.55] "" Vector__XXX
 SG_ VoltOverallParam_MinCellVoltage : 7|8@0+ (0.01,2) [2|4.55] "V" Vector__XXX
 SG_ VoltOverallParam_MaxCellVoltage : 15|8@0+ (0.01,2) [2|4.55] "V" Vector__XXX
 SG_ VoltOverallParam_AvrgCellVoltage : 23|8@0+ (0.01,2) [2|4.55] "V" Vector__XXX

BO_ 441 Overall_Parameters2_Std: 8 Vector__XXX
 SG_ OverallParams2_NumberOfCells : 7|16@0+ (1,0) [0|65535] "" Vector__XXX

BO_ 2578776068 Overall_Parameters2_Ext: 8 Vector__XXX
 SG_ OverallParams2_NumberOfCells : 7|16@0+ (1,0) [0|65535] "" Vector__XXX

BO_ 2578777872 Serial_Number_Ext: 4 EMUS_BMS
 SG_ Serial_Number_Number : 7|32@0+ (1,0) [0|4294967295] "" Vector__XXX

BO_ 677 Serial_Number_Std: 4 EMUS_BMS
 SG_ Serial_Number_Number : 7|32@0+ (1,0) [0|4294967295] "" Vector__XXX

BO_ 661 Firmware_Version_Std: 4 EMUS_BMS
 SG_ Version_PatchVersion : 31|8@0+ (1,0) [0|65535] "" Vector__XXX
 SG_ Version_RevisionVersion : 23|8@0+ (1,0) [0|255] "" Vector__XXX
 SG_ Version_MinorVersion : 15|8@0+ (1,0) [0|255] "" Vector__XXX
 SG_ Version_MajorVersion : 7|8@0+ (1,0) [0|255] "" Vector__XXX

BO_ 2578777856 Firmware_Version_Ext: 4 EMUS_BMS
 SG_ Version_PatchVersion : 31|8@0+ (1,0) [0|65535] "" Vector__XXX
 SG_ Version_RevisionVersion : 23|8@0+ (1,0) [0|255] "" Vector__XXX
 SG_ Version_MinorVersion : 15|8@0+ (1,0) [0|255] "" Vector__XXX
 SG_ Version_MajorVersion : 7|8@0+ (1,0) [0|255] "" Vector__XXX

BO_ 2578776070 Energy_Parameters_2_Ext: 8 EMUS_BMS
 SG_ Energy_EstimatedConsumption : 7|16@0+ (1,0) [0|65535] "Wh" Vector__XXX
 SG_ Energy_EstimatedEnergy : 23|16@0+ (0.01,0) [0|655.35] "kWh" Vector__XXX
 SG_ Energy_EstimatedDistanceLeft : 39|16@0+ (0.01,0) [0|655.35] "" Vector__XXX
 SG_ Energy_DistanceTraveled : 55|16@0+ (0.01,0) [0|655.35] "" Vector__XXX

BO_ 568 Login_Set_Password_Std: 8 VEHICLE_CONTROL_UNIT
 SG_ Character_0 : 7|8@0+ (1,0) [0|255] "" Vector__XXX
 SG_ Character_1 : 15|8@0+ (1,0) [0|255] "" Vector__XXX
 SG_ Character_2 : 23|8@0+ (1,0) [0|255] "" Vector__XXX
 SG_ Character_3 : 31|8@0+ (1,0) [0|255] "" Vector__XXX
 SG_ Character_4 : 39|8@0+ (1,0) [0|255] "" Vector__XXX
 SG_ Character_5 : 47|8@0+ (1,0) [0|255] "" Vector__XXX
 SG_ Character_6 : 55|8@0+ (1,0) [0|255] "" Vector__XXX
 SG_ Character_7 : 63|8@0+ (1,0) [0|255] "" Vector__XXX

BO_ 2578776073 Battery_Volt_2_Overall_Param_Ext: 8 EMUS_BMS
 SG_ VoltOverallParams_TotalVolt : 31|32@0+ (0.01,0) [0|429496729.5] "V" Vector__XXX
 SG_ VoltOverallParam_MinCellVoltage : 7|8@0+ (0.01,2) [2|4.55] "V" Vector__XXX
 SG_ VoltOverallParam_MaxCellVoltage : 15|8@0+ (0.01,2) [2|4.55] "V" Vector__XXX
 SG_ VoltOverallParam_AvrgCellVoltage : 23|8@0+ (0.01,2) [2|4.55] "V" Vector__XXX

BO_ 2578776064 Overall_Parameters_Ext: 8 EMUS_BMS
 SG_ OverallParams_IgnitionKey : 0|1@0+ (1,0) [0|1] "" Vector__XXX
 SG_ OverallParams_ChargerMains : 1|1@0+ (1,0) [0|1] "" Vector__XXX
 SG_ OverallParams_FastCharge : 2|1@0+ (1,0) [0|1] "" Vector__XXX
 SG_ OverallParams_LeakageSensor : 3|1@0+ (1,0) [0|1] "" Vector__XXX
 SG_ OverallParams_ChargerEnable : 8|1@0+ (1,0) [0|1] "" Vector__XXX
 SG_ OverallParams_HeaterEnable : 9|1@0+ (1,0) [0|1] "" Vector__XXX
 SG_ OverallParams_BatteryContactor : 10|1@0+ (1,0) [0|1] "" Vector__XXX
 SG_ OverallParams_BatteryFan : 11|1@0+ (1,0) [0|1] "" Vector__XXX
 SG_ OverallParams_PowerReduction : 12|1@0+ (1,0) [0|1] "" Vector__XXX
 SG_ OverallParams_DCDC_Control : 14|1@0+ (1,0) [0|1] "" Vector__XXX
 SG_ OverallParams_ContactorPreCharge : 15|1@0+ (1,0) [0|1] "" Vector__XXX
 SG_ OverallParams_NumberOfCells_MSB : 23|8@0+ (1,0) [0|255] "" Vector__XXX
 SG_ OverallParams_ChargingStage : 31|8@0+ (1,0) [0|255] "" Vector__XXX
 SG_ OverallParams_ChrgStageDurat : 39|16@0+ (1,0) [0|65535] "min" Vector__XXX
 SG_ OverallParams_LastChargingError : 55|8@0+ (1,0) [0|255] "" Vector__XXX
 SG_ OverallParams_ChargingInterlock : 13|1@0+ (1,0) [0|1] "" Vector__XXX
 SG_ OverallParams_NumberOfCells_LSB : 63|8@0+ (1,0) [0|255] "" Vector__XXX

BO_ 2578776071 Diagnostic_Codes_Ext: 8 EMUS_BMS
 SG_ DiagnosticCodes_VoltReadDev : 23|1@0+ (1,0) [0|1] "" Vector__XXX
 SG_ DiagnosticCodes_MS_CanMalfRed : 36|1@0+ (1,0) [0|1] "" Vector__XXX
 SG_ DiagnosticCodes_MS_ConfMMRed : 35|1@0+ (1,0) [0|1] "" Vector__XXX
 SG_ DiagnosticCodes_CellOvrHeatRed : 37|1@0+ (1,0) [0|1] "" Vector__XXX
 SG_ DiagnosticCodes_ModOvrHeatRed : 34|1@0+ (1,0) [0|1] "" Vector__XXX
 SG_ DiagnosticCodes_DischgOvrCurrRed : 33|1@0+ (1,0) [0|1] "" Vector__XXX
 SG_ DiagnosticCodes_UnderVoltRed : 32|1@0+ (1,0) [0|1] "" Vector__XXX
 SG_ DiagnosticCodes_ParStringVoltDev : 21|1@0+ (1,0) [0|1] "" Vector__XXX
 SG_ DiagnosticCodes_CellTempValid : 61|1@0+ (1,0) [0|1] "" Vector__XXX
 SG_ DiagnosticCodes_BatChrgFinished : 60|1@0+ (1,0) [0|1] "" Vector__XXX
 SG_ DiagnosticCodes_NumOfCellsValid : 59|1@0+ (1,0) [0|1] "" Vector__XXX
 SG_ DiagnosticCodes_CellBalancValid : 58|1@0+ (1,0) [0|1] "" Vector__XXX
 SG_ DiagnosticCodes_CellModTempValid : 57|1@0+ (1,0) [0|1] "" Vector__XXX
 SG_ DiagnosticCodes_CellVoltValidity : 56|1@0+ (1,0) [0|1] "" Vector__XXX
 SG_ DiagnosticCodes_PackVoltDev : 17|1@0+ (1,0) [0|1] "" Vector__XXX
 SG_ DiagnosticCodes_CellVoltDev : 16|1@0+ (1,0) [0|1] "" Vector__XXX
 SG_ DiagnosticCodes_ExtTempSensLoss : 19|1@0+ (1,0) [0|1] "" Vector__XXX
 SG_ DiagnosticCodes_VoltExtTempValid : 22|1@0+ (1,0) [0|1] "" Vector__XXX
 SG_ DiagnosticCodes_Wirebreak : 20|1@0+ (1,0) [0|1] "" Vector__XXX
 SG_ DiagnosticCodes_ChargerConnected : 10|1@0+ (1,0) [0|1] "" Vector__XXX
 SG_ DiagnosticCodes_PackOverVoltage : 14|1@0+ (1,0) [0|1] "" Vector__XXX
 SG_ DiagnosticCodes_CellModUnderHeat : 18|1@0+ (1,0) [0|0] "" Vector__XXX
 SG_ DiagnosticCodes_CellUnderVoltage : 0|1@0+ (1,0) [0|1] "" Vector__XXX
 SG_ DiagnosticCodes_CellOverVoltage : 1|1@0+ (1,0) [0|1] "" Vector__XXX
 SG_ DiagnosticCodes_DchrgOvrCurrent : 2|1@0+ (1,0) [0|1] "" Vector__XXX
 SG_ DiagnosticCodes_ChrgOverCurrent : 3|1@0+ (1,0) [0|1] "" Vector__XXX
 SG_ DiagnosticCodes_Leakage : 5|1@0+ (1,0) [0|1] "" Vector__XXX
 SG_ DiagnosticCodes_NoCellComm : 6|1@0+ (1,0) [0|1] "" Vector__XXX
 SG_ DiagnosticCodes_CellModOverHeat : 4|1@0+ (1,0) [0|1] "" Vector__XXX
 SG_ DiagnosticCodes_CellOverHeat : 11|1@0+ (1,0) [0|1] "" Vector__XXX
 SG_ DiagnosticCodes_NoCurrentSensor : 12|1@0+ (1,0) [0|1] "" Vector__XXX
 SG_ DiagnosticCodes_PackUnderVoltage : 13|1@0+ (1,0) [0|1] "" Vector__XXX
 SG_ DiagnosticCodes_MS_ConfError : 7|1@0+ (1,0) [0|1] "" Vector__XXX
 SG_ DiagnosticCodes_CellUnderHeat : 15|1@0+ (1,0) [0|1] "" Vector__XXX
 SG_ DiagnosticCodes_MSIntCANError : 8|1@0+ (1,0) [0|1] "" Vector__XXX
 SG_ DiagnosticCodes_MSCommCANErr : 9|1@0+ (1,0) [0|1] "" Vector__XXX

BO_ 2578776066 Cell_Mod_Temp_Overall_Param_Ext: 8 EMUS_BMS
 SG_ CellModOverallPar_MinCellModTemp : 7|8@0+ (1,-100) [-100|155] "C" Vector__XXX
 SG_ CellModOverallPar_MaxCellModTemp : 15|8@0+ (1,-100) [-100|155] "C" Vector__XXX
 SG_ CellModOverallPar_AvgCellModTemp : 23|8@0+ (1,-100) [-100|155] "C" Vector__XXX

BO_ 2578776072 Cell_Temp_Overall_Params_Ext: 8 EMUS_BMS
 SG_ CellOverallPar_AvgCellTemp : 23|8@0+ (1,-100) [-100|155] "C" Vector__XXX
 SG_ CellOverallPar_MaxCellTemp : 15|8@0+ (1,-100) [-100|155] "C" Vector__XXX
 SG_ CellOverallPar_MinCellTemp : 7|8@0+ (1,-100) [-100|155] "C" Vector__XXX

BO_ 2578776067 Cell_Balanc_Rate_Overall_Par_Ext: 8 EMUS_BMS
 SG_ CellBalancPar_MinCellBalancRate : 7|8@0+ (0.392156862745098,0) [0|100] "%" Vector__XXX
 SG_ CellBalancPar_MaxCellBalancRate : 15|8@0+ (0.392156862745098,0) [0|100] "%" Vector__XXX
 SG_ CellBalancPar_AvgCellBalancRate : 23|8@0+ (0.392156862745098,0) [0|100] "%" Vector__XXX

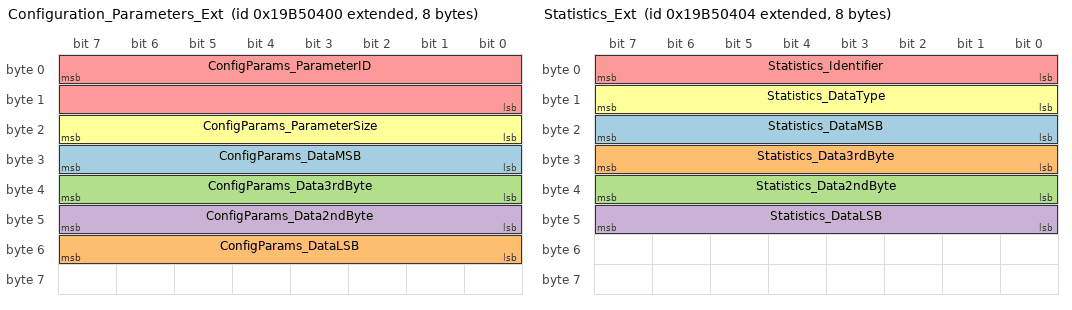
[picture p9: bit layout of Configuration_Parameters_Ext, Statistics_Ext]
BO_ 2578777088 Configuration_Parameters_Ext: 8 EMUS_BMS
 SG_ ConfigParams_DataMSB : 31|8@0+ (1,0) [0|255] "" Vector__XXX
 SG_ ConfigParams_DataLSB : 55|8@0+ (1,0) [0|255] "" Vector__XXX
 SG_ ConfigParams_Data3rdByte : 39|8@0+ (1,0) [0|255] "" Vector__XXX
 SG_ ConfigParams_Data2ndByte : 47|8@0+ (1,0) [0|255] "" Vector__XXX
 SG_ ConfigParams_ParameterID : 7|16@0+ (1,0) [0|65535] "" Vector__XXX
 SG_ ConfigParams_ParameterSize : 23|8@0+ (1,0) [0|255] "" Vector__XXX

BO_ 2578777090 Login_Level_Ext: 8 EMUS_BMS
 SG_ LoginLevel : 7|8@0+ (1,0) [0|255] "" Vector__XXX

BO_ 2578777089 Contactor_Control_Ext: 8 VEHICLE_CONTROL_UNIT
 SG_ ContactorControl_ContactorState : 7|8@0+ (1,0) [0|255] "" Vector__XXX

BO_ 2578777600 Energy_Parameters_Ext: 8 EMUS_BMS
 SG_ Energy_DistanceTraveled : 55|16@0+ (0.01,0) [0|655.35] "" Vector__XXX
 SG_ Energy_EstimatedDistanceLeft : 39|16@0+ (0.01,0) [0|655.35] "" Vector__XXX
 SG_ Energy_EstimatedEnergy : 23|16@0+ (0.01,0) [0|655.35] "kWh" Vector__XXX
 SG_ Energy_EstimatedConsumption : 7|16@0+ (1,0) [0|65535] "Wh" Vector__XXX

BO_ 2578777344 State_Of_Charge_Param_Ext: 8 EMUS_BMS
 SG_ SOC_Params_EstimatedSOH : 63|8@0+ (1,0) [0|255] "%" Vector__XXX
 SG_ SOCParams_Current : 7|16@0- (0.1,0) [-3276.8|3276.7] "A" Vector__XXX
 SG_ SOCParams_Estimated_Charge : 23|16@0+ (0.1,0) [0|6553.5] "Ah" Vector__XXX
 SG_ SOCParams_EstimatedUserSOC : 55|8@0+ (1,0) [0|255] "%" Vector__XXX

BO_ 2578777092 Statistics_Ext: 8 EMUS_BMS
 SG_ Statistics_DataMSB : 23|8@0+ (1,0) [0|255] "" Vector__XXX
 SG_ Statistics_Data3rdByte : 31|8@0+ (1,0) [0|255] "" Vector__XXX
 SG_ Statistics_Data2ndByte : 39|8@0+ (1,0) [0|255] "" Vector__XXX
 SG_ Statistics_DataLSB : 47|8@0+ (1,0) [0|255] "" Vector__XXX
 SG_ Statistics_Identifier : 7|8@0+ (1,0) [0|255] "" Vector__XXX
 SG_ Statistics_DataType : 15|8@0+ (1,0) [0|255] "" Vector__XXX

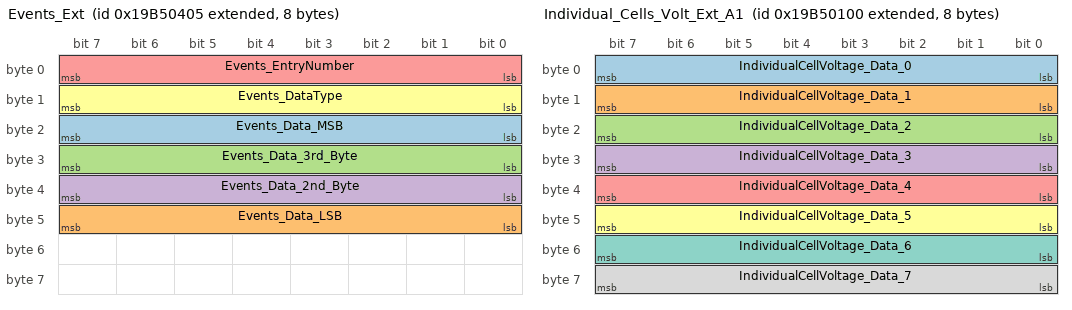
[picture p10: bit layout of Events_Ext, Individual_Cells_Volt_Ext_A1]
BO_ 2578777093 Events_Ext: 8 EMUS_BMS
 SG_ Events_Data_MSB : 23|8@0+ (1,0) [0|255] "" Vector__XXX
 SG_ Events_Data_LSB : 47|8@0+ (1,0) [0|255] "" Vector__XXX
 SG_ Events_Data_3rd_Byte : 31|8@0+ (1,0) [0|255] "" Vector__XXX
 SG_ Events_Data_2nd_Byte : 39|8@0+ (1,0) [0|255] "" Vector__XXX
 SG_ Events_EntryNumber : 7|8@0+ (1,0) [0|255] "" Vector__XXX
 SG_ Events_DataType : 15|8@0+ (1,0) [0|255] "" Vector__XXX

BO_ 2578776320 Individual_Cells_Volt_Ext_A1: 8 EMUS_BMS
 SG_ IndividualCellVoltage_Data_0 : 7|8@0+ (0.01,2) [2|4.55] "V" Vector__XXX
 SG_ IndividualCellVoltage_Data_1 : 15|8@0+ (0.01,2) [2|4.55] "V" Vector__XXX
 SG_ IndividualCellVoltage_Data_2 : 23|8@0+ (0.01,2) [2|4.55] "V" Vector__XXX
 SG_ IndividualCellVoltage_Data_3 : 31|8@0+ (0.01,2) [2|4.55] "V" Vector__XXX
 SG_ IndividualCellVoltage_Data_4 : 39|8@0+ (0.01,2) [2|4.55] "V" Vector__XXX
 SG_ IndividualCellVoltage_Data_5 : 47|8@0+ (0.01,2) [2|4.55] "V" Vector__XXX
 SG_ IndividualCellVoltage_Data_6 : 55|8@0+ (0.01,2) [2|4.55] "V" Vector__XXX
 SG_ IndividualCellVoltage_Data_7 : 63|8@0+ (0.01,2) [2|4.55] "V" Vector__XXX

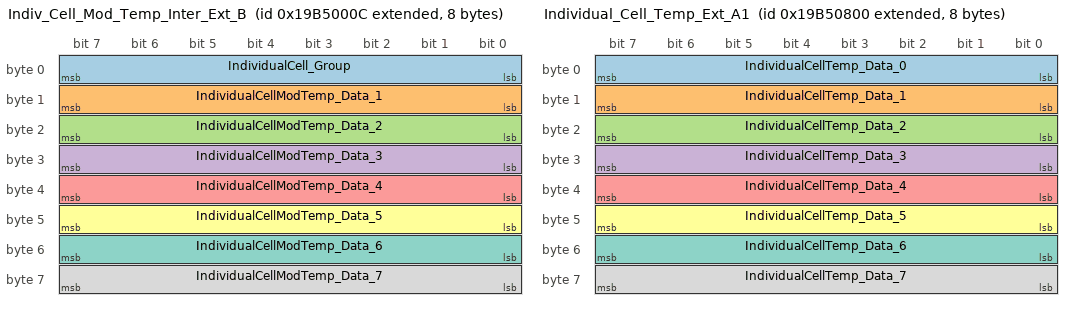
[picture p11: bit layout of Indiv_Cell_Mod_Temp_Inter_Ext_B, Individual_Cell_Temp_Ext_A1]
BO_ 2578776076 Indiv_Cell_Mod_Temp_Inter_Ext_B: 8 EMUS_BMS
 SG_ IndividualCell_Group : 7|8@0+ (1,0) [0|255] "" Vector__XXX
 SG_ IndividualCellModTemp_Data_1 : 15|8@0+ (1,-100) [-100|155] "C" Vector__XXX
 SG_ IndividualCellModTemp_Data_2 : 23|8@0+ (1,-100) [-100|155] "C" Vector__XXX
 SG_ IndividualCellModTemp_Data_3 : 31|8@0+ (1,-100) [-100|155] "C" Vector__XXX
 SG_ IndividualCellModTemp_Data_4 : 39|8@0+ (1,-100) [-100|155] "C" Vector__XXX
 SG_ IndividualCellModTemp_Data_5 : 47|8@0+ (1,-100) [-100|155] "C" Vector__XXX
 SG_ IndividualCellModTemp_Data_6 : 55|8@0+ (1,-100) [-100|155] "C" Vector__XXX
 SG_ IndividualCellModTemp_Data_7 : 63|8@0+ (1,-100) [-100|155] "C" Vector__XXX

BO_ 2578778112 Individual_Cell_Temp_Ext_A1: 8 EMUS_BMS
 SG_ IndividualCellTemp_Data_0 : 7|8@0+ (1,-100) [-100|155] "C" Vector__XXX
 SG_ IndividualCellTemp_Data_1 : 15|8@0+ (1,-100) [-100|155] "C" Vector__XXX
 SG_ IndividualCellTemp_Data_2 : 23|8@0+ (1,-100) [-100|155] "C" Vector__XXX
 SG_ IndividualCellTemp_Data_3 : 31|8@0+ (1,-100) [-100|155] "C" Vector__XXX
 SG_ IndividualCellTemp_Data_4 : 39|8@0+ (1,-100) [-100|155] "C" Vector__XXX
 SG_ IndividualCellTemp_Data_5 : 47|8@0+ (1,-100) [-100|155] "C" Vector__XXX
 SG_ IndividualCellTemp_Data_6 : 55|8@0+ (1,-100) [-100|155] "C" Vector__XXX
 SG_ IndividualCellTemp_Data_7 : 63|8@0+ (1,-100) [-100|155] "C" Vector__XXX

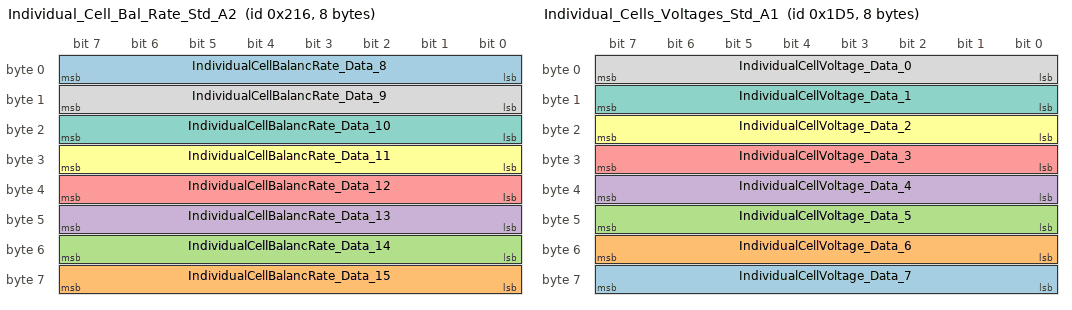
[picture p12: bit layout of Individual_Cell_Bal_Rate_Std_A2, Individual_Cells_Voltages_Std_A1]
BO_ 534 Individual_Cell_Bal_Rate_Std_A2: 8 EMUS_BMS
 SG_ IndividualCellBalancRate_Data_8 : 7|8@0+ (0.392156862745098,0) [0|100] "%" Vector__XXX
 SG_ IndividualCellBalancRate_Data_15 : 63|8@0+ (0.392156862745098,0) [0|100] "%" Vector__XXX
 SG_ IndividualCellBalancRate_Data_14 : 55|8@0+ (0.392156862745098,0) [0|100] "%" Vector__XXX
 SG_ IndividualCellBalancRate_Data_13 : 47|8@0+ (0.392156862745098,0) [0|100] "%" Vector__XXX
 SG_ IndividualCellBalancRate_Data_12 : 39|8@0+ (0.392156862745098,0) [0|100] "%" Vector__XXX
 SG_ IndividualCellBalancRate_Data_11 : 31|8@0+ (0.392156862745098,0) [0|100] "%" Vector__XXX
 SG_ IndividualCellBalancRate_Data_10 : 23|8@0+ (0.392156862745098,0) [0|100] "%" Vector__XXX
 SG_ IndividualCellBalancRate_Data_9 : 15|8@0+ (0.392156862745098,0) [0|100] "%" Vector__XXX

BO_ 256 Overall_Parameters_Std: 8 EMUS_BMS
 SG_ OverallParams_NumberOfCells_LSB : 63|8@0+ (1,0) [0|255] "" Vector__XXX
 SG_ OverallParams_LastChargingError : 55|8@0+ (1,0) [0|255] "" Vector__XXX
 SG_ OverallParams_ChrgStageDurat : 39|16@0+ (1,0) [0|65535] "min" Vector__XXX
 SG_ OverallParams_ChargingStage : 31|8@0+ (1,0) [0|255] "" Vector__XXX
 SG_ OverallParams_NumberOfCells_MSB : 23|8@0+ (1,0) [0|255] "" Vector__XXX
 SG_ OverallParams_ContactorPreCharge : 15|1@0+ (1,0) [0|1] "" Vector__XXX
 SG_ OverallParams_DCDC_Control : 14|1@0+ (1,0) [0|1] "" Vector__XXX
 SG_ OverallParams_ChargingInterlock : 13|1@0+ (1,0) [0|1] "" Vector__XXX
 SG_ OverallParams_PowerReduction : 12|1@0+ (1,0) [0|1] "" Vector__XXX
 SG_ OverallParams_BatteryFan : 11|1@0+ (1,0) [0|1] "" Vector__XXX
 SG_ OverallParams_BatteryContactor : 10|1@0+ (1,0) [0|1] "" Vector__XXX
 SG_ OverallParams_HeaterEnable : 9|1@0+ (1,0) [0|1] "" Vector__XXX
 SG_ OverallParams_ChargerEnable : 8|1@0+ (1,0) [0|1] "" Vector__XXX
 SG_ OverallParams_LeakageSensor : 3|1@0+ (1,0) [0|1] "" Vector__XXX
 SG_ OverallParams_FastCharge : 2|1@0+ (1,0) [0|1] "" Vector__XXX
 SG_ OverallParams_ChargerMains : 1|1@0+ (1,0) [0|1] "" Vector__XXX
 SG_ OverallParams_IgnitionKey : 0|1@0+ (1,0) [0|1] "" Vector__XXX

BO_ 263 Diagnostic_Codes_Std: 8 EMUS_BMS
 SG_ DiagnosticCodes_VoltReadDev : 23|1@0+ (1,0) [0|1] "" Vector__XXX
 SG_ DiagnosticCodes_MS_CanMalfRed : 36|1@0+ (1,0) [0|1] "" Vector__XXX
 SG_ DiagnosticCodes_MS_ConfMMRed : 35|1@0+ (1,0) [0|1] "" Vector__XXX
 SG_ DiagnosticCodes_CellOvrHeatRed : 37|1@0+ (1,0) [0|1] "" Vector__XXX
 SG_ DiagnosticCodes_ModOvrHeatRed : 34|1@0+ (1,0) [0|1] "" Vector__XXX
 SG_ DiagnosticCodes_DischgOvrCurrRed : 33|1@0+ (1,0) [0|1] "" Vector__XXX
 SG_ DiagnosticCodes_UnderVoltRed : 32|1@0+ (1,0) [0|1] "" Vector__XXX
 SG_ DiagnosticCodes_ParStringVoltDev : 21|1@0+ (1,0) [0|1] "" Vector__XXX
 SG_ DiagnosticCodes_CellTempValid : 56|1@0+ (1,0) [0|1] "" Vector__XXX
 SG_ DiagnosticCodes_BatChrgFinished : 61|1@0+ (1,0) [0|1] "" Vector__XXX
 SG_ DiagnosticCodes_NumOfCellsValid : 60|1@0+ (1,0) [0|1] "" Vector__XXX
 SG_ DiagnosticCodes_CellBalancValid : 59|1@0+ (1,0) [0|1] "" Vector__XXX
 SG_ DiagnosticCodes_CellModTempValid : 58|1@0+ (1,0) [0|1] "" Vector__XXX
 SG_ DiagnosticCodes_CellVoltValidity : 57|1@0+ (1,0) [0|1] "" Vector__XXX
 SG_ DiagnosticCodes_PackVoltDev : 17|1@0+ (1,0) [0|1] "" Vector__XXX
 SG_ DiagnosticCodes_CellVoltDev : 16|1@0+ (1,0) [0|1] "" Vector__XXX
 SG_ DiagnosticCodes_ExtTempSensLoss : 19|1@0+ (1,0) [0|1] "" Vector__XXX
 SG_ DiagnosticCodes_VoltExtTempValid : 22|1@0+ (1,0) [0|1] "" Vector__XXX
 SG_ DiagnosticCodes_Wirebreak : 20|1@0+ (1,0) [0|1] "" Vector__XXX
 SG_ DiagnosticCodes_ChargerConnected : 10|1@0+ (1,0) [0|1] "" Vector__XXX
 SG_ DiagnosticCodes_PackOverVoltage : 14|1@0+ (1,0) [0|1] "" Vector__XXX
 SG_ DiagnosticCodes_CellModUnderHeat : 18|1@0+ (1,0) [0|0] "" Vector__XXX
 SG_ DiagnosticCodes_PackUnderVoltage : 13|1@0+ (1,0) [0|1] "" Vector__XXX
 SG_ DiagnosticCodes_NoCurrentSensor : 12|1@0+ (1,0) [0|1] "" Vector__XXX
 SG_ DiagnosticCodes_CellOverHeat : 11|1@0+ (1,0) [0|1] "" Vector__XXX
 SG_ DiagnosticCodes_MSCommCANErr : 9|1@0+ (1,0) [0|1] "" Vector__XXX
 SG_ DiagnosticCodes_MSIntCANError : 8|1@0+ (1,0) [0|1] "" Vector__XXX
 SG_ DiagnosticCodes_CellUnderHeat : 15|1@0+ (1,0) [0|1] "" Vector__XXX
 SG_ DiagnosticCodes_CellModOverHeat : 4|1@0+ (1,0) [0|1] "" Vector__XXX
 SG_ DiagnosticCodes_MS_ConfError : 7|1@0+ (1,0) [0|1] "" Vector__XXX
 SG_ DiagnosticCodes_NoCellComm : 6|1@0+ (1,0) [0|1] "" Vector__XXX
 SG_ DiagnosticCodes_Leakage : 5|1@0+ (1,0) [0|1] "" Vector__XXX
 SG_ DiagnosticCodes_ChrgOverCurrent : 3|1@0+ (1,0) [0|1] "" Vector__XXX
 SG_ DiagnosticCodes_DchrgOvrCurrent : 2|1@0+ (1,0) [0|1] "" Vector__XXX
 SG_ DiagnosticCodes_CellOverVoltage : 1|1@0+ (1,0) [0|1] "" Vector__XXX
 SG_ DiagnosticCodes_CellUnderVoltage : 0|1@0+ (1,0) [0|1] "" Vector__XXX

BO_ 446 Battery_Volt_2_Overall_Param_Std: 8 EMUS_BMS
 SG_ VoltOverallParams_TotalVolt : 31|32@0+ (0.01,0) [0|42949672.95] "V" Vector__XXX
 SG_ VoltOverallParam_AvrgCellVoltage : 23|8@0+ (0.01,2) [2|4.55] "V" Vector__XXX
 SG_ VoltOverallParam_MaxCellVoltage : 15|8@0+ (0.01,2) [2|4.55] "V" Vector__XXX
 SG_ VoltOverallParam_MinCellVoltage : 7|8@0+ (0.01,2) [2|4.55] "V" Vector__XXX

BO_ 258 Cell_Mod_Temp_Overall_Param_Std: 8 EMUS_BMS
 SG_ CellModOverallPar_AvgCellModTemp : 23|8@0+ (1,-100) [-100|155] "C" Vector__XXX
 SG_ CellModOverallPar_MaxCellModTemp : 15|8@0+ (1,-100) [-100|155] "C" Vector__XXX
 SG_ CellModOverallPar_MinCellModTemp : 7|8@0+ (1,-100) [-100|155] "C" Vector__XXX

BO_ 264 Cell_Temp_Overall_Param_Std: 8 EMUS_BMS
 SG_ CellOverallPar_MinCellTemp : 7|8@0+ (1,-100) [-100|155] "C" Vector__XXX
 SG_ CellOverallPar_MaxCellTemp : 15|8@0+ (1,-100) [-100|155] "C" Vector__XXX
 SG_ CellOverallPar_AvgCellTemp : 23|8@0+ (1,-100) [-100|155] "C" Vector__XXX

BO_ 259 Cell_Balanc_Rate_Overall_Par_Std: 8 EMUS_BMS
 SG_ CellBalancPar_AvgCellBalancRate : 23|8@0+ (0.392156862745098,0) [0|100] "%" Vector__XXX
 SG_ CellBalancPar_MaxCellBalancRate : 15|8@0+ (0.392156862745098,0) [0|100] "%" Vector__XXX
 SG_ CellBalancPar_MinCellBalancRate : 7|8@0+ (0.392156862745098,0) [0|100] "%" Vector__XXX

BO_ 469 Individual_Cells_Voltages_Std_A1: 8 EMUS_BMS
 SG_ IndividualCellVoltage_Data_7 : 63|8@0+ (0.01,2) [2|4.55] "V" Vector__XXX
 SG_ IndividualCellVoltage_Data_6 : 55|8@0+ (0.01,2) [2|4.55] "V" Vector__XXX
 SG_ IndividualCellVoltage_Data_5 : 47|8@0+ (0.01,2) [2|4.55] "V" Vector__XXX
 SG_ IndividualCellVoltage_Data_4 : 39|8@0+ (0.01,2) [2|4.55] "V" Vector__XXX
 SG_ IndividualCellVoltage_Data_3 : 31|8@0+ (0.01,2) [2|4.55] "V" Vector__XXX
 SG_ IndividualCellVoltage_Data_2 : 23|8@0+ (0.01,2) [2|4.55] "V" Vector__XXX
 SG_ IndividualCellVoltage_Data_1 : 15|8@0+ (0.01,2) [2|4.55] "V" Vector__XXX
 SG_ IndividualCellVoltage_Data_0 : 7|8@0+ (0.01,2) [2|4.55] "V" Vector__XXX

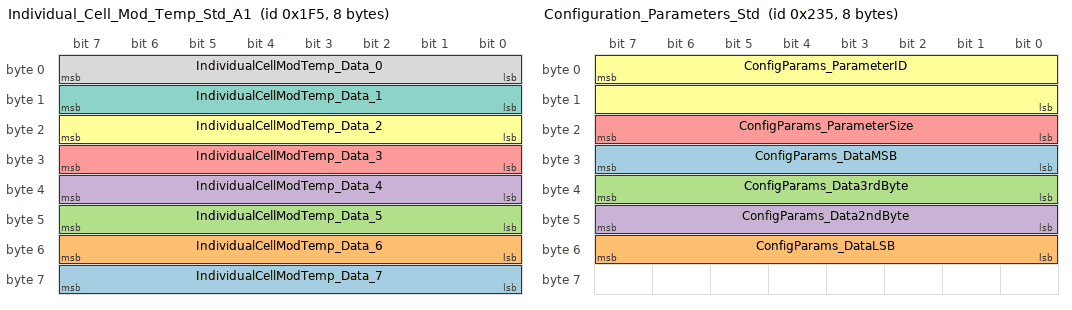
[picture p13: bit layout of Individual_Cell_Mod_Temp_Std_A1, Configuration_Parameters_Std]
BO_ 501 Individual_Cell_Mod_Temp_Std_A1: 8 EMUS_BMS
 SG_ IndividualCellModTemp_Data_7 : 63|8@0+ (1,-100) [-100|155] "C" Vector__XXX
 SG_ IndividualCellModTemp_Data_6 : 55|8@0+ (1,-100) [-100|155] "C" Vector__XXX
 SG_ IndividualCellModTemp_Data_5 : 47|8@0+ (1,-100) [-100|155] "C" Vector__XXX
 SG_ IndividualCellModTemp_Data_4 : 39|8@0+ (1,-100) [-100|155] "C" Vector__XXX
 SG_ IndividualCellModTemp_Data_3 : 31|8@0+ (1,-100) [-100|155] "C" Vector__XXX
 SG_ IndividualCellModTemp_Data_2 : 23|8@0+ (1,-100) [-100|155] "C" Vector__XXX
 SG_ IndividualCellModTemp_Data_1 : 15|8@0+ (1,-100) [-100|155] "C" Vector__XXX
 SG_ IndividualCellModTemp_Data_0 : 7|8@0+ (1,-100) [-100|155] "C" Vector__XXX

BO_ 565 Configuration_Parameters_Std: 8 EMUS_BMS
 SG_ ConfigParams_DataMSB : 31|8@0+ (1,0) [0|255] "" Vector__XXX
 SG_ ConfigParams_DataLSB : 55|8@0+ (1,0) [0|255] "" Vector__XXX
 SG_ ConfigParams_Data3rdByte : 39|8@0+ (1,0) [0|255] "" Vector__XXX
 SG_ ConfigParams_Data2ndByte : 47|8@0+ (1,0) [0|255] "" Vector__XXX
 SG_ ConfigParams_ParameterSize : 23|8@0+ (1,0) [0|255] "" Vector__XXX
 SG_ ConfigParams_ParameterID : 7|16@0+ (1,0) [0|65535] "" Vector__XXX

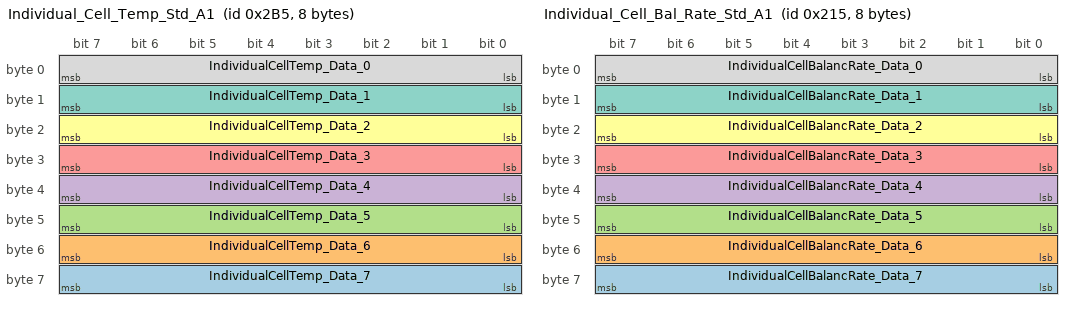
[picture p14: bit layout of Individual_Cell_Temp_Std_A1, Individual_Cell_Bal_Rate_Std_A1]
BO_ 693 Individual_Cell_Temp_Std_A1: 8 EMUS_BMS
 SG_ IndividualCellTemp_Data_7 : 63|8@0+ (1,-100) [-100|155] "C" Vector__XXX
 SG_ IndividualCellTemp_Data_6 : 55|8@0+ (1,-100) [-100|155] "C" Vector__XXX
 SG_ IndividualCellTemp_Data_5 : 47|8@0+ (1,-100) [-100|155] "C" Vector__XXX
 SG_ IndividualCellTemp_Data_4 : 39|8@0+ (1,-100) [-100|155] "C" Vector__XXX
 SG_ IndividualCellTemp_Data_3 : 31|8@0+ (1,-100) [-100|155] "C" Vector__XXX
 SG_ IndividualCellTemp_Data_2 : 23|8@0+ (1,-100) [-100|155] "C" Vector__XXX
 SG_ IndividualCellTemp_Data_1 : 15|8@0+ (1,-100) [-100|155] "C" Vector__XXX
 SG_ IndividualCellTemp_Data_0 : 7|8@0+ (1,-100) [-100|155] "C" Vector__XXX

BO_ 533 Individual_Cell_Bal_Rate_Std_A1: 8 EMUS_BMS
 SG_ IndividualCellBalancRate_Data_7 : 63|8@0+ (0.392156862745098,0) [0|100] "%" Vector__XXX
 SG_ IndividualCellBalancRate_Data_6 : 55|8@0+ (0.392156862745098,0) [0|100] "%" Vector__XXX
 SG_ IndividualCellBalancRate_Data_5 : 47|8@0+ (0.392156862745098,0) [0|100] "%" Vector__XXX
 SG_ IndividualCellBalancRate_Data_4 : 39|8@0+ (0.392156862745098,0) [0|100] "%" Vector__XXX
 SG_ IndividualCellBalancRate_Data_3 : 31|8@0+ (0.392156862745098,0) [0|100] "%" Vector__XXX
 SG_ IndividualCellBalancRate_Data_2 : 23|8@0+ (0.392156862745098,0) [0|100] "%" Vector__XXX
 SG_ IndividualCellBalancRate_Data_1 : 15|8@0+ (0.392156862745098,0) [0|100] "%" Vector__XXX
 SG_ IndividualCellBalancRate_Data_0 : 7|8@0+ (0.392156862745098,0) [0|100] "%" Vector__XXX

BO_ 553 Contactor_Control_Std: 8 VEHICLE_CONTROL_UNIT
 SG_ ContactorControl_ContactorState : 7|8@0+ (1,0) [0|255] "" Vector__XXX

BO_ 262 Energy_Parameters_Std: 8 EMUS_BMS
 SG_ Energy_DistanceTraveled : 55|16@0+ (0.01,0) [0|655.35] "" Vector__XXX
 SG_ Energy_EstimatedDistanceLeft : 39|16@0+ (0.01,0) [0|655.35] "" Vector__XXX
 SG_ Energy_EstimatedEnergy : 23|16@0+ (0.01,0) [0|655.35] "kWh" Vector__XXX
 SG_ Energy_EstimatedConsumption : 7|16@0+ (1,0) [0|65535] "Wh" Vector__XXX

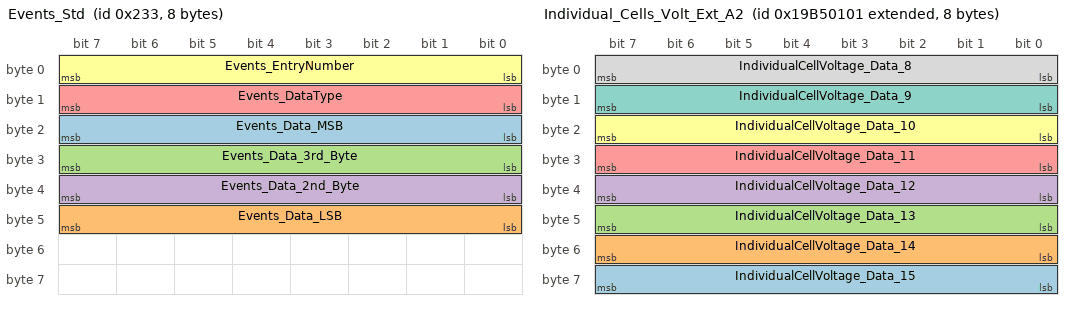
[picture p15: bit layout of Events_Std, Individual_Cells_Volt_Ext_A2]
BO_ 563 Events_Std: 8 EMUS_BMS
 SG_ Events_Data_MSB : 23|8@0+ (1,0) [0|255] "" Vector__XXX
 SG_ Events_Data_LSB : 47|8@0+ (1,0) [0|255] "" Vector__XXX
 SG_ Events_Data_3rd_Byte : 31|8@0+ (1,0) [0|255] "" Vector__XXX
 SG_ Events_Data_2nd_Byte : 39|8@0+ (1,0) [0|255] "" Vector__XXX
 SG_ Events_DataType : 15|8@0+ (1,0) [0|255] "" Vector__XXX
 SG_ Events_EntryNumber : 7|8@0+ (1,0) [0|255] "" Vector__XXX

BO_ 567 Login_Level_Std: 8 EMUS_BMS
 SG_ LoginLevel : 7|8@0+ (1,0) [0|255] "" Vector__XXX

BO_ 261 State_Of_Charge_Param_Std: 8 EMUS_BMS
 SG_ SOC_Params_EstimatedSOH : 63|8@0+ (1,0) [0|255] "%" Vector__XXX
 SG_ SOCParams_Estimated_Charge : 23|16@0+ (0.1,0) [0|6553.5] "Ah" Vector__XXX
 SG_ SOCParams_EstimatedUserSOC : 55|8@0+ (1,0) [0|255] "%" Vector__XXX
 SG_ SOCParams_Current : 7|16@0- (0.1,0) [-3276.8|3276.7] "A" Vector__XXX

BO_ 562 Statistics_Std: 8 EMUS_BMS
 SG_ Statistics_Identifier : 7|8@0+ (1,0) [0|255] "" Vector__XXX
 SG_ Statistics_Data3rdByte : 31|8@0+ (1,0) [0|255] "" Vector__XXX
 SG_ Statistics_Data2ndByte : 39|8@0+ (1,0) [0|255] "" Vector__XXX
 SG_ Statistics_DataLSB : 47|8@0+ (1,0) [0|255] "" Vector__XXX
 SG_ Statistics_DataMSB : 23|8@0+ (1,0) [0|255] "" Vector__XXX
 SG_ Statistics_DataType : 15|8@0+ (1,0) [0|255] "" Vector__XXX

BO_ 2578776321 Individual_Cells_Volt_Ext_A2: 8 EMUS_BMS
 SG_ IndividualCellVoltage_Data_15 : 63|8@0+ (0.01,2) [2|4.55] "V" Vector__XXX
 SG_ IndividualCellVoltage_Data_14 : 55|8@0+ (0.01,2) [2|4.55] "V" Vector__XXX
 SG_ IndividualCellVoltage_Data_13 : 47|8@0+ (0.01,2) [2|4.55] "V" Vector__XXX
 SG_ IndividualCellVoltage_Data_12 : 39|8@0+ (0.01,2) [2|4.55] "V" Vector__XXX
 SG_ IndividualCellVoltage_Data_11 : 31|8@0+ (0.01,2) [2|4.55] "V" Vector__XXX
 SG_ IndividualCellVoltage_Data_10 : 23|8@0+ (0.01,2) [2|4.55] "V" Vector__XXX
 SG_ IndividualCellVoltage_Data_9 : 15|8@0+ (0.01,2) [2|4.55] "V" Vector__XXX
 SG_ IndividualCellVoltage_Data_8 : 7|8@0+ (0.01,2) [2|4.55] "V" Vector__XXX

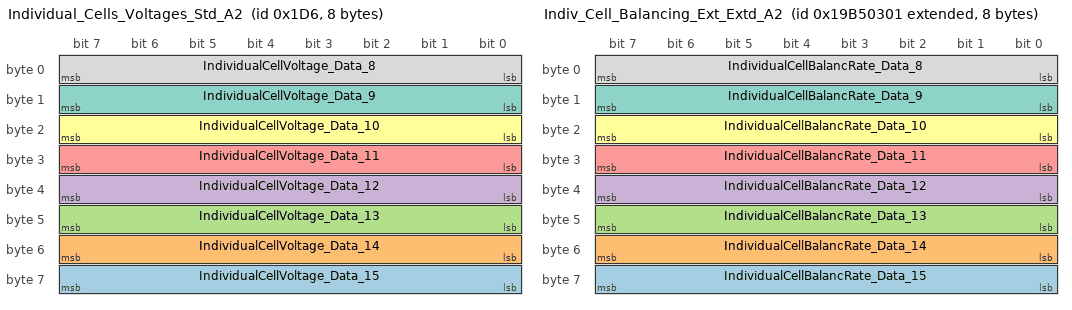
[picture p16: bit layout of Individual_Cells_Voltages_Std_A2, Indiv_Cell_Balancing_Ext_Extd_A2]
BO_ 470 Individual_Cells_Voltages_Std_A2: 8 EMUS_BMS
 SG_ IndividualCellVoltage_Data_15 : 63|8@0+ (0.01,2) [2|4.55] "V" Vector__XXX
 SG_ IndividualCellVoltage_Data_14 : 55|8@0+ (0.01,2) [2|4.55] "V" Vector__XXX
 SG_ IndividualCellVoltage_Data_13 : 47|8@0+ (0.01,2) [2|4.55] "V" Vector__XXX
 SG_ IndividualCellVoltage_Data_12 : 39|8@0+ (0.01,2) [2|4.55] "V" Vector__XXX
 SG_ IndividualCellVoltage_Data_11 : 31|8@0+ (0.01,2) [2|4.55] "V" Vector__XXX
 SG_ IndividualCellVoltage_Data_10 : 23|8@0+ (0.01,2) [2|4.55] "V" Vector__XXX
 SG_ IndividualCellVoltage_Data_9 : 15|8@0+ (0.01,2) [2|4.55] "V" Vector__XXX
 SG_ IndividualCellVoltage_Data_8 : 7|8@0+ (0.01,2) [2|4.55] "V" Vector__XXX

BO_ 2578776833 Indiv_Cell_Balancing_Ext_Extd_A2: 8 EMUS_BMS
 SG_ IndividualCellBalancRate_Data_15 : 63|8@0+ (0.392156862745098,0) [0|100] "%" Vector__XXX
 SG_ IndividualCellBalancRate_Data_14 : 55|8@0+ (0.392156862745098,0) [0|100] "%" Vector__XXX
 SG_ IndividualCellBalancRate_Data_13 : 47|8@0+ (0.392156862745098,0) [0|100] "%" Vector__XXX
 SG_ IndividualCellBalancRate_Data_12 : 39|8@0+ (0.392156862745098,0) [0|100] "%" Vector__XXX
 SG_ IndividualCellBalancRate_Data_11 : 31|8@0+ (0.392156862745098,0) [0|100] "%" Vector__XXX
 SG_ IndividualCellBalancRate_Data_10 : 23|8@0+ (0.392156862745098,0) [0|100] "%" Vector__XXX
 SG_ IndividualCellBalancRate_Data_9 : 15|8@0+ (0.392156862745098,0) [0|100] "%" Vector__XXX
 SG_ IndividualCellBalancRate_Data_8 : 7|8@0+ (0.392156862745098,0) [0|100] "%" Vector__XXX

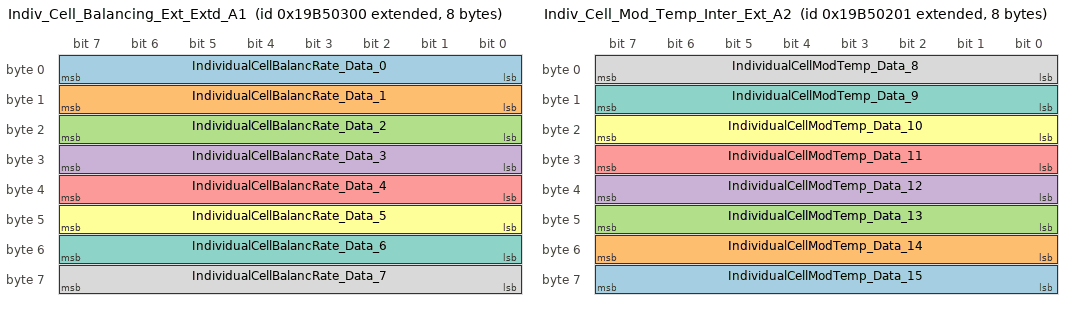
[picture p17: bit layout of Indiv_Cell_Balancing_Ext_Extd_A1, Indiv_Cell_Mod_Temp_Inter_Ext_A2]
BO_ 2578776832 Indiv_Cell_Balancing_Ext_Extd_A1: 8 EMUS_BMS
 SG_ IndividualCellBalancRate_Data_0 : 7|8@0+ (0.392156862745098,0) [0|100] "%" Vector__XXX
 SG_ IndividualCellBalancRate_Data_1 : 15|8@0+ (0.392156862745098,0) [0|100] "%" Vector__XXX
 SG_ IndividualCellBalancRate_Data_2 : 23|8@0+ (0.392156862745098,0) [0|100] "%" Vector__XXX
 SG_ IndividualCellBalancRate_Data_3 : 31|8@0+ (0.392156862745098,0) [0|100] "%" Vector__XXX
 SG_ IndividualCellBalancRate_Data_4 : 39|8@0+ (0.392156862745098,0) [0|100] "%" Vector__XXX
 SG_ IndividualCellBalancRate_Data_5 : 47|8@0+ (0.392156862745098,0) [0|100] "%" Vector__XXX
 SG_ IndividualCellBalancRate_Data_6 : 55|8@0+ (0.392156862745098,0) [0|100] "%" Vector__XXX
 SG_ IndividualCellBalancRate_Data_7 : 63|8@0+ (0.392156862745098,0) [0|100] "%" Vector__XXX

BO_ 2578776577 Indiv_Cell_Mod_Temp_Inter_Ext_A2: 8 EMUS_BMS
 SG_ IndividualCellModTemp_Data_15 : 63|8@0+ (1,-100) [-100|155] "C" Vector__XXX
 SG_ IndividualCellModTemp_Data_14 : 55|8@0+ (1,-100) [-100|155] "C" Vector__XXX
 SG_ IndividualCellModTemp_Data_13 : 47|8@0+ (1,-100) [-100|155] "C" Vector__XXX
 SG_ IndividualCellModTemp_Data_12 : 39|8@0+ (1,-100) [-100|155] "C" Vector__XXX
 SG_ IndividualCellModTemp_Data_11 : 31|8@0+ (1,-100) [-100|155] "C" Vector__XXX
 SG_ IndividualCellModTemp_Data_10 : 23|8@0+ (1,-100) [-100|155] "C" Vector__XXX
 SG_ IndividualCellModTemp_Data_9 : 15|8@0+ (1,-100) [-100|155] "C" Vector__XXX
 SG_ IndividualCellModTemp_Data_8 : 7|8@0+ (1,-100) [-100|155] "C" Vector__XXX

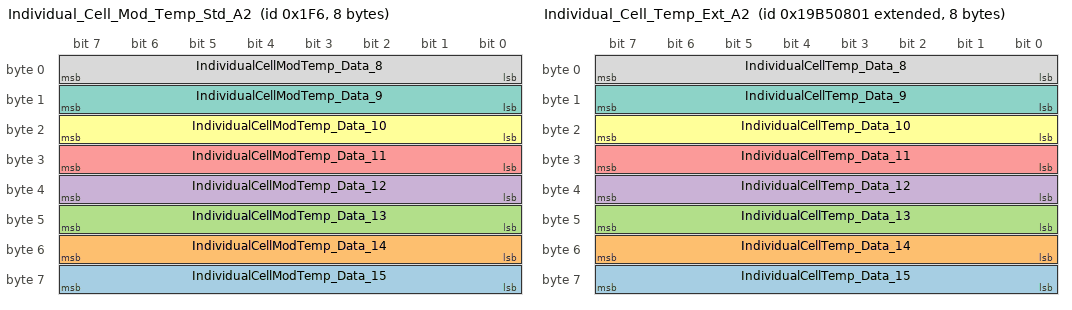
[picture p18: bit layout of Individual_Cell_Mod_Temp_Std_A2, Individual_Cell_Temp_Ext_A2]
BO_ 502 Individual_Cell_Mod_Temp_Std_A2: 8 EMUS_BMS
 SG_ IndividualCellModTemp_Data_15 : 63|8@0+ (1,-100) [-100|155] "C" Vector__XXX
 SG_ IndividualCellModTemp_Data_14 : 55|8@0+ (1,-100) [-100|155] "C" Vector__XXX
 SG_ IndividualCellModTemp_Data_13 : 47|8@0+ (1,-100) [-100|155] "C" Vector__XXX
 SG_ IndividualCellModTemp_Data_12 : 39|8@0+ (1,-100) [-100|155] "C" Vector__XXX
 SG_ IndividualCellModTemp_Data_11 : 31|8@0+ (1,-100) [-100|155] "C" Vector__XXX
 SG_ IndividualCellModTemp_Data_10 : 23|8@0+ (1,-100) [-100|155] "C" Vector__XXX
 SG_ IndividualCellModTemp_Data_9 : 15|8@0+ (1,-100) [-100|155] "C" Vector__XXX
 SG_ IndividualCellModTemp_Data_8 : 7|8@0+ (1,-100) [-100|155] "C" Vector__XXX

BO_ 2578778113 Individual_Cell_Temp_Ext_A2: 8 EMUS_BMS
 SG_ IndividualCellTemp_Data_15 : 63|8@0+ (1,-100) [-100|155] "C" Vector__XXX
 SG_ IndividualCellTemp_Data_14 : 55|8@0+ (1,-100) [-100|155] "C" Vector__XXX
 SG_ IndividualCellTemp_Data_13 : 47|8@0+ (1,-100) [-100|155] "C" Vector__XXX
 SG_ IndividualCellTemp_Data_12 : 39|8@0+ (1,-100) [-100|155] "C" Vector__XXX
 SG_ IndividualCellTemp_Data_11 : 31|8@0+ (1,-100) [-100|155] "C" Vector__XXX
 SG_ IndividualCellTemp_Data_10 : 23|8@0+ (1,-100) [-100|155] "C" Vector__XXX
 SG_ IndividualCellTemp_Data_9 : 15|8@0+ (1,-100) [-100|155] "C" Vector__XXX
 SG_ IndividualCellTemp_Data_8 : 7|8@0+ (1,-100) [-100|155] "C" Vector__XXX

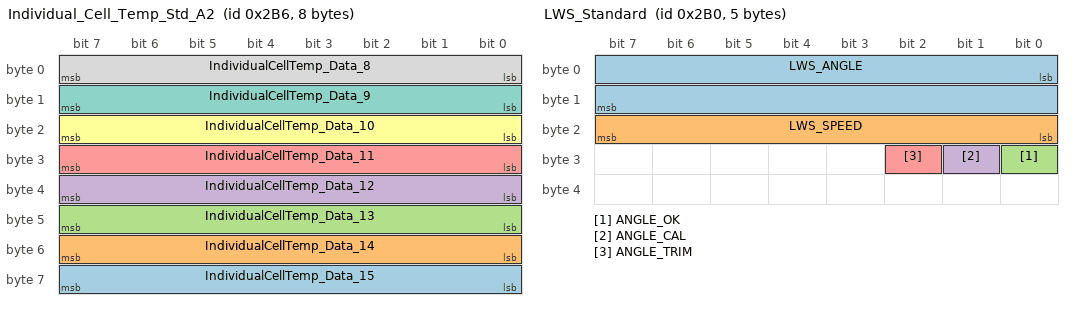
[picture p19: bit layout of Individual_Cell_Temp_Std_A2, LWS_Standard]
BO_ 694 Individual_Cell_Temp_Std_A2: 8 EMUS_BMS
 SG_ IndividualCellTemp_Data_15 : 63|8@0+ (1,-100) [-100|155] "C" Vector__XXX
 SG_ IndividualCellTemp_Data_14 : 55|8@0+ (1,-100) [-100|155] "C" Vector__XXX
 SG_ IndividualCellTemp_Data_13 : 47|8@0+ (1,-100) [-100|155] "C" Vector__XXX
 SG_ IndividualCellTemp_Data_12 : 39|8@0+ (1,-100) [-100|155] "C" Vector__XXX
 SG_ IndividualCellTemp_Data_11 : 31|8@0+ (1,-100) [-100|155] "C" Vector__XXX
 SG_ IndividualCellTemp_Data_10 : 23|8@0+ (1,-100) [-100|155] "C" Vector__XXX
 SG_ IndividualCellTemp_Data_9 : 15|8@0+ (1,-100) [-100|155] "C" Vector__XXX
 SG_ IndividualCellTemp_Data_8 : 7|8@0+ (1,-100) [-100|155] "C" Vector__XXX

BO_ 2578777091 Login_Set_Password_Status_Ext: 8 VEHICLE_CONTROL_UNIT
 SG_ LoginSetPasswordStatus : 7|8@0+ (1,0) [0|255] "" Vector__XXX

BO_ 1313 Neuro1_Battery_Data: 8 EMUS_BMS
 SG_ Neuro1_DepthOfDischarge : 24|16@1+ (0.1,0) [0|1000] "%" Vector__XXX

BO_ 1314 Neuro2_Battery_Data: 8 EMUS_BMS
 SG_ Neuro2_BatteryVoltMinDischrg : 32|16@1+ (0.1,0) [0|6553.5] "V" Vector__XXX
 SG_ Neuro2_Dischrg_Current_Warn : 48|16@1+ (0.1,0) [0|6553.5] "A" Vector__XXX

BO_ 1315 Neuro3_Battery_Data: 8 EMUS_BMS
 SG_ Neuro3_BatVoltMaxRegen : 0|16@1+ (0.1,0) [0|6553.5] "V" Vector__XXX
 SG_ Neuro3_ChrgCurrentLimit : 16|16@1+ (0.1,0) [0|6553.5] "A" Vector__XXX

BO_ 1328 Neuro4_BimData: 8 EMUS_BMS
 SG_ Neuro4_Discharge_Control : 0|1@1+ (1,0) [0|1] "" Vector__XXX
 SG_ Neuro4_Regeneration_Control : 1|1@1+ (1,0) [0|1] "" Vector__XXX
 SG_ Neuro4_AverageCellTemperature : 16|8@1+ (1,40) [0|255] "C" Vector__XXX
 SG_ Neuro4_CellTemperatureValid : 24|8@1+ (1,0) [0|255] "" Vector__XXX
 SG_ Neuro4_ChargingStatus : 8|8@1+ (1,0) [0|255] "" Vector__XXX

BO_ 572 ChargingStation_Std: 8 VEHICLE_CONTROL_UNIT
 SG_ ChargingStation_DCCurrentLim : 7|16@0+ (0.1,0) [0|6553.5] "A" Vector__XXX
 SG_ ChargingStation_ACCurrentLim : 23|16@0+ (0.1,0) [0|6553.5] "A" Vector__XXX
 SG_ ChargingStation_ACVoltage : 39|16@0+ (0.1,0) [0|6553.5] "V" Vector__XXX
 SG_ ChargingStation_PowerLimit : 55|16@0+ (10,0) [0|65535] "W" Vector__XXX

BO_ 2578777095 ChargingStation_Ext: 8 VEHICLE_CONTROL_UNIT
 SG_ ChargingStation_PowerLimit : 55|16@0+ (10,0) [0|65535] "W" Vector__XXX
 SG_ ChargingStation_ACVoltage : 39|16@0+ (0.1,0) [0|6553.5] "V" Vector__XXX
 SG_ ChargingStation_ACCurrentLim : 23|16@0+ (0.1,0) [0|6553.5] "A" Vector__XXX
 SG_ ChargingStation_DCCurrentLim : 7|16@0+ (0.1,0) [0|6553.5] "A" Vector__XXX

BO_ 688 LWS_Standard : 5 Vector__XXX
 SG_ LWS_ANGLE : 0|16@1- (0.1,0) [-780|780] "deg" Vector__XXX
 SG_ LWS_SPEED : 16|8@1+ (4,0) [0|1016] "deg/s" Vector__XXX
 SG_ ANGLE_OK : 24|1@1+ (1,0) [0|1] "" Vector__XXX
 SG_ ANGLE_CAL : 25|1@1+ (1,0) [0|1] "" Vector__XXX
 SG_ ANGLE_TRIM : 26|1@1+ (1,0) [0|1] "" Vector__XXX

BO_ 1984 LWS_Config : 5 Vector__XXX
 SG_ Command_Code_Word : 0|3@1+ (1,0) [0|8] "" Vector__XXX

BO_ 3 CAN_VCU_TO_ACU_ID: 1 VEHICLE_CONTROL_UNIT
 SG_ HTL_CH_ID_VCU_TO_ACU_HEARTBEAT : 0|8@1+ (1,0) [0|255] ""  ACCUMULATOR_CONTROL_UNIT

BO_ 2 CAN_ACU_TO_VCU_ID: 1 ACCUMULATOR_CONTROL_UNIT
 SG_ HTL_CH_ID_ACU_TO_VCU_HEARTBEAT : 0|8@1+ (1,0) [0|255] ""  VEHICLE_CONTROL_UNIT

BO_ 1 CAN_VCU_SET_ACB_STATE_ID: 1 VEHICLE_CONTROL_UNIT
 SG_ HTL_CH_ID_CAR_STATE : 0|8@1+ (1,0) [0|255] "" Vector__XXX

CM_ BU_ VEHICLE_CONTROL_UNIT "The system vehicle control unit";
CM_ BU_ MOTOR_CONTROLLER "The Cascadia Motion inverter";
CM_ BU_ EMUS_BMS "BMS Master";
CM_ BU_ U2C "Delphi DC/DC Converter";
CM_ BO_ 2147486373 "This is a made up message from 5 signals that just had no message from Cascadias DBC file online. ";
CM_ BO_ 194 "The inverter response to each Parameter message that is received.";
CM_ SG_ 194 INV_Write_Success "0=Write failure, 1=Success";
CM_ SG_ 194 INV_Data_Response "All EEPROM data is 16 bits and is contained in bytes 4 and 5. Bytes 6 and 7 should be ignored.";
CM_ SG_ 194 INV_Parameter_Address_Response "Valid EEPROM Parameter CAN addresses are between 100 and 499.";
CM_ BO_ 193 "Parameter Message sent as needed by VCU to request info, change EEPROM, or command a function.";
CM_ BO_ 192 "The command message is used to transmit data to the controller. This message is sent from a user supplied external controller to the PMxxx controller.";
CM_ BO_ 176 "To enable fast message set CAN ACTIVE MSGS HI WORD to 0xFFFE.  Setting to default value of 0xFFFF will disable the fast message.";
CM_ SG_ 173 INV_Iq_Command "The commanded Q-axis current";
CM_ SG_ 173 INV_Id_Command "The commanded D-axis current";
CM_ SG_ 173 INV_Flux_Weakening_Output "This is the current output of the flux regulator.";
CM_ SG_ 173 INV_Modulation_Index "This is the modulation index. The scale factor is x100. To get the actual modulation index divide the value by 100.";
CM_ SG_ 172 INV_Power_On_Timer "Updated every 3 msec. This will roll over in approximately 150 days!";
CM_ SG_ 172 INV_Torque_Feedback "Estimated motor torque feedback";
CM_ SG_ 172 INV_Commanded_Torque "The commanded Torque";
CM_ SG_ 171 INV_Run_Fault_Hi "Each bit represents a fault. Please refer to PM100 Users Manual for details.";
CM_ SG_ 171 INV_Post_Fault_Hi "Each bit represents a fault. Please refer to PM100 Users Manual for details.";
CM_ SG_ 171 INV_Run_Fault_Lo "Each bit represents a fault. Please refer to PM100 Users Manual for details.";
CM_ SG_ 171 INV_Post_Fault_Lo "Each bit represents a fault. Please refer to PM100 Users Manual for details.";
CM_ SG_ 170 INV_Direction_Command "1 = Forward 0 = 'Reverse' if inverter enabled  & 'Stopped' if inverter is disabled";
CM_ SG_ 170 INV_Inverter_Enable_State "0=Inverter Disabled, 1=Inverter Enabled";
CM_ SG_ 170 INV_Relay_3_Status "0=OFF, 1=ON";
CM_ SG_ 170 INV_Relay_4_Status "0=OFF, 1=ON";
CM_ SG_ 170 INV_Relay_2_Status "0=OFF, 1=ON";
CM_ SG_ 170 INV_Inverter_Run_Mode "0=Torque Mode, 1=Speed Mode";
CM_ SG_ 170 INV_Inverter_Command_Mode "0=CAN mode, 1=VSM mode";
CM_ SG_ 170 INV_Relay_1_Status "0=OFF, 1=ON";
CM_ SG_ 170 INV_Inverter_State "Different states for the inverter state machine";
CM_ SG_ 170 INV_VSM_State "Different states for the vehicle state machine";
CM_ SG_ 170 INV_Inverter_Enable_Lockout "0=Lockout Disabled, 1=Lockout Enabled";
CM_ SG_ 170 INV_Inverter_Discharge_State "0 = Disabled, 1 = Enabled, 2 = Speed Check, 3 = Active, 4 = Complete";
CM_ SG_ 170 INV_Relay_5_Status "0=OFF, 1=ON";
CM_ SG_ 170 INV_Relay_6_Status "0=OFF, 1=ON";
CM_ SG_ 170 INV_BMS_Active "0 = BMS Not Active, 1 = BMS Active";
CM_ SG_ 170 INV_BMS_Torque_Limiting "0 = Not Limiting, 1 = Limiting";
CM_ SG_ 170 INV_Max_Speed_Limiting "0 = Not Limiting, 1 = torque limiting due to maximum speed";
CM_ SG_ 170 INV_Low_Speed_Limiting "0 = Not Limiting, 1 = Current limiting due to low motor speed";
CM_ SG_ 170 INV_Rolling_Counter "The current rolling counter value.";
CM_ SG_ 170 INV_PWM_Frequency "The inverter PWM frequency";
CM_ SG_ 170 INV_Start_Mode_Active "If in Key Switch Mode 1 then indicates status of Start input being applied.  0 = not active, 1 = active";
CM_ SG_ 169 INV_Reference_Voltage_12_0 "12V Input Voltage";
CM_ SG_ 169 INV_Reference_Voltage_5_0 "Transducer voltage";
CM_ SG_ 169 INV_Reference_Voltage_2_5 "Internal reference voltage";
CM_ SG_ 169 INV_Reference_Voltage_1_5 "Internal reference voltage";
CM_ SG_ 168 INV_Iq "The measured Iq current";
CM_ SG_ 168 INV_Id "The measured Id current";
CM_ SG_ 168 INV_Flux_Feedback "The estimated flux";
CM_ SG_ 168 INV_Flux_Command "The commanded flux";
CM_ SG_ 167 INV_VBC_Vq_Voltage "Measured value of the voltage between Phase B and Phase C";
CM_ SG_ 167 INV_VAB_Vd_Voltage "Measured value of the voltage betwen phase A and Phase B";
CM_ SG_ 167 INV_Output_Voltage "The calculated value of the output voltage, in peak line-neutral volts";
CM_ SG_ 167 INV_DC_Bus_Voltage "The actual measured value of the DC bus voltage";
CM_ SG_ 166 INV_DC_Bus_Current "The Calculated DC Bus Current";
CM_ SG_ 166 INV_Phase_C_Current "The measured value of Phase C current";
CM_ SG_ 166 INV_Phase_B_Current "The measured value of Phase B current";
CM_ SG_ 166 INV_Phase_A_Current "The measured value of Phase A current";
CM_ SG_ 165 INV_Delta_Resolver_Filtered "Used in calibration of resolver angle adjustment.";
CM_ SG_ 165 INV_Electrical_Output_Frequency "The actual electrical frequency of the inverter";
CM_ SG_ 165 INV_Motor_Speed "The measured speed of the motor";
CM_ SG_ 165 INV_Motor_Angle_Electrical "The Electrical Angle of the motor as read by the encoder or resolver";
CM_ SG_ 164 INV_Digital_Input_5 "Status of Digital Input #5";
CM_ SG_ 164 INV_Digital_Input_4 "Status of Digital Input #4";
CM_ SG_ 164 INV_Digital_Input_3 "Status of Digital Input #3";
CM_ SG_ 164 INV_Digital_Input_2 "Status of Digital Input #2";
CM_ SG_ 164 INV_Digital_Input_1 "Status of Digital Input #1";
CM_ SG_ 164 INV_Digital_Input_6 "Status of Digital Input #6";
CM_ SG_ 164 INV_Digital_Input_7 "Status of Digital Input #7";
CM_ SG_ 164 INV_Digital_Input_8 "Status of Digital Input #8";
CM_ SG_ 163 INV_Analog_Input_4 "Voltage on Analog Input #4";
CM_ SG_ 163 INV_Analog_Input_3 "Voltage on Analog Input #3";
CM_ SG_ 163 INV_Analog_Input_2 "Voltage on Analog Input #2";
CM_ SG_ 163 INV_Analog_Input_1 "Voltage on Analog Input #1";
CM_ SG_ 163 INV_Analog_Input_5 "Voltage on Analog Input #5";
CM_ SG_ 163 INV_Analog_Input_6 "Voltage on Analog Input #6";
CM_ SG_ 162 INV_Torque_Shudder "Shudder compensation value of torque";
CM_ SG_ 162 INV_Motor_Temperature "Motor Temperature Sensor";
CM_ SG_ 162 INV_RTD5_Temperature "RTD 5 (PT100) Temperature (Gen 2 only)";
CM_ SG_ 162 INV_RTD4_Temperature "RTD 4 (PT100) Temperature (Gen 2 only)";
CM_ SG_ 161 INV_RTD3_Temperature "RTD input 3 (PT1000) Temperature";
CM_ SG_ 161 INV_RTD2_Temperature "RTD input 2 (PT1000) Temperature";
CM_ SG_ 161 INV_RTD1_Temperature "RTD input 1 (PT1000) Temperature";
CM_ SG_ 161 INV_Control_Board_Temperature "Control Board Temperature";
CM_ SG_ 160 INV_Gate_Driver_Board "Gate Driver Board Temperature";
CM_ SG_ 160 INV_Module_C "IGBT Module C Temperature";
CM_ SG_ 160 INV_Module_B "IGBT Module B Temperature";
CM_ SG_ 160 INV_Module_A "IGBT Module A Temperature";
CM_ BO_ 471 "Enable message sent to Delphi DC/DC converter.";
CM_ BO_ 514 "Message sent by BMS for inverter DC current limiting.";
CM_ SG_ 514 INV_Max_Discharge_Current "Maximum discharge current from BMS";
CM_ SG_ 514 INV_Max_Charge_Current "Maximum charge current from BMS";
CM_ BO_ 188 "Response from Delphi DC/DC converter.";
CM_ BO_ 275 "Individual Cell Balancing Rates Standard Option A";
CM_ BO_ 2578776077 "Individual Cell Balancing Rate Extended Option A";
CM_ BO_ 276 "Individual Cell Temperatures Standard Option A";
CM_ BO_ 2578776078 "Individual Cell Temperatures Extended Option A";
CM_ BO_ 274 "Individual Cell Module Temperature Standard Option A";
CM_ BO_ 2578776576 "Individual Cell Module Temperatures Extended Option A";
CM_ BO_ 2578776075 "Individual Cells Voltages Extended Option A";
CM_ BO_ 2578776070 "Energy Parameters Extended";
CM_ BO_ 2578776073 "Battery Voltage Overall Parameters Extended";
CM_ BO_ 2578776064 "Overall Parameters Extended";
CM_ BO_ 2578776071 "Diagnostic Codes Extended";
CM_ BO_ 2578776066 "Cell Module Temperature Overall Parameters Extended";
CM_ BO_ 2578776072 "Cell Temperature Overall Parameters Extended";
CM_ BO_ 2578776067 "Cell Balancing Overall Parameters Extended";
CM_ BO_ 2578777088 "Configuration Parameters Extended";
CM_ BO_ 2578777090 "Login Request Response Extended";
CM_ BO_ 2578777089 "Contactor Control Extended";
CM_ BO_ 2578777600 "Energy Parameters Extended";
CM_ BO_ 2578777344 "State Of Charge Parameters Extended";
CM_ BO_ 2578777092 "Statistics Extended";
CM_ BO_ 2578777093 "Events Extended";
CM_ BO_ 2578776320 "Individual Cells Voltages Extended Option A";
CM_ BO_ 2578776076 "Individual Cell Module Temperatures Extended Option A";
CM_ BO_ 2578778112 "Individual Cell Temperatures Extended Option A";
CM_ BO_ 534 "Individual Cell Balancing Rates Standard Option B";
CM_ SG_ 534 IndividualCellBalancRate_Data_8 "Individual Cells Group Value for CAN Option B";
CM_ BO_ 256 "Overall Parameters Standard";
CM_ BO_ 263 "Diagnostic Codes Standard";
CM_ BO_ 446 "Battery Voltage Overall Parameters Standard";
CM_ BO_ 258 "Cell Module Overall Parameters Standard";
CM_ BO_ 264 "Cell Temperature Overall Params Standard";
CM_ BO_ 259 "Cell Bancing Rate Overall Params Standard";
CM_ BO_ 469 "Individual Cells Voltages Standard Option A";
CM_ BO_ 501 "Individual Cell Module Temperature Standard Option A";
CM_ BO_ 693 "Individual Cell Temperatures Standard Option A";
CM_ BO_ 533 "Individual Cell Balancing Rates Standard Option A";
CM_ BO_ 553 "Contactor Control Standard";
CM_ BO_ 262 "Energy Parameters Standard";
CM_ BO_ 261 "State Of Charge Parameters Standard";
CM_ BO_ 562 "Statistics Standard";
CM_ BO_ 2578776321 "Individual Cells Voltages Extended Option B";
CM_ SG_ 2578776321 IndividualCellVoltage_Data_8 "Individual Cells Group Value for CAN Option B";
CM_ BO_ 470 "Individual Cells Voltages Standard Option B";
CM_ SG_ 470 IndividualCellVoltage_Data_8 "Individual Cells Group Value for CAN Option B";
CM_ BO_ 2578776833 "Individual Cell Balancing Rate Extended Option B";
CM_ SG_ 2578776833 IndividualCellBalancRate_Data_8 "Individual Cells Group Value for CAN Option B";
CM_ BO_ 2578776832 "Individual Cell Balancing Rate Extended Option A";
CM_ BO_ 2578776577 "Individual Cell Modules Temperature Extended Option B";
CM_ SG_ 2578776577 IndividualCellModTemp_Data_8 "Individual Cells Group Value for CAN Option B";
CM_ BO_ 502 "Individual Cell Module Temperature Standard Option B";
CM_ SG_ 502 IndividualCellModTemp_Data_8 "Individual Cells Group Value for CAN Option B";
CM_ BO_ 2578778113 "Individual Cell Temperatures Extended Option B";
CM_ SG_ 2578778113 IndividualCellTemp_Data_8 "Individual Cells Group Value for CAN Option B";
CM_ BO_ 694 "Individual Cell Temperature Standard Option B";
CM_ SG_ 694 IndividualCellTemp_Data_8 "Individual Cells Group Value for CAN Option B";
CM_ SG_ 1328 Neuro4_Discharge_Control "Contactor State";
CM_ SG_ 1328 Neuro4_Regeneration_Control "if max cell voltage is less than fully charge minus balancing range, then allow regeneration";
BA_DEF_ BO_  "GenMsgCycleTime" INT 0 100000;
BA_DEF_  "MultiplexExtEnabled" ENUM  "No","Yes";
BA_DEF_  "BusType" STRING ;
BA_DEF_ SG_  "SystemSignalLongSymbol" STRING ;
BA_DEF_DEF_  "GenMsgCycleTime" 0;
BA_DEF_DEF_  "MultiplexExtEnabled" "No";
BA_DEF_DEF_  "BusType" "CAN";
BA_DEF_DEF_  "SystemSignalLongSymbol" "";
BA_ "MultiplexExtEnabled" 1;
BA_ "GenMsgCycleTime" BO_ 1549 250;
BA_ "GenMsgCycleTime" BO_ 1037 100;
BA_ "GenMsgCycleTime" BO_ 269 20;
BA_ "GenMsgCycleTime" BO_ 192 5;
BA_ "GenMsgCycleTime" BO_ 176 3;
BA_ "GenMsgCycleTime" BO_ 175 3;
BA_ "GenMsgCycleTime" BO_ 172 10;
BA_ "GenMsgCycleTime" BO_ 171 100;
BA_ "GenMsgCycleTime" BO_ 170 100;
BA_ "GenMsgCycleTime" BO_ 169 100;
BA_ "GenMsgCycleTime" BO_ 168 10;
BA_ "GenMsgCycleTime" BO_ 167 10;
BA_ "GenMsgCycleTime" BO_ 166 10;
BA_ "GenMsgCycleTime" BO_ 165 10;
BA_ "GenMsgCycleTime" BO_ 164 10;
BA_ "GenMsgCycleTime" BO_ 163 10;
BA_ "GenMsgCycleTime" BO_ 162 100;
BA_ "GenMsgCycleTime" BO_ 161 100;
BA_ "GenMsgCycleTime" BO_ 160 100;
BA_ "SystemSignalLongSymbol" SG_ 193 VCU_INV_Parameter_Address_Comman "VCU_INV_Parameter_Address_Command";
BA_ "SystemSignalLongSymbol" SG_ 188 INV_HV_Input_Current_Sensor_Vali "INV_HV_Input_Current_Sensor_Validity";
VAL_ 573 Charger_Control 2 "REQUEST_FOR_STATE" 1 "CHARGING_ENABLED" 0 "CHARGING_DISABLED" ;
VAL_ 2578777096 Charger_Control 2 "REQUEST_FOR_STATE" 1 "CHARGING_ENABLED" 0 "CHARGING_DISABLED" ;
VAL_ 2566869221 Charger_StartingState 1 "Bat Disconnecting Or Reverse" 0 "Normal" ;
VAL_ 2566869221 Charger_InputVoltageProtection 1 "Incrrt Input V/Chrg Stop Working" 0 "Normal" ;
VAL_ 2566869221 Charger_HighTempProtection 1 "Over Temperature Protection" 0 "Normal" ;
VAL_ 2566869221 Charger_HardwareFailure 1 "Hardware Failure" 0 "Normal" ;
VAL_ 2566869221 Charger_CommunicationState 1 "Comm Receiving Time-out" 0 "Normal" ;
VAL_ 2550588916 Bms_Control 1 "Stop Charging" 0 "Start Charging" ;
VAL_ 2578776064 OverallParams_IgnitionKey 0 "OFF" 1 "ON" ;
VAL_ 2578776064 OverallParams_ChargerMains 0 "OFF" 1 "ON" ;
VAL_ 2578776064 OverallParams_FastCharge 0 "OFF" 1 "ON" ;
VAL_ 2578776064 OverallParams_LeakageSensor 0 "OFF" 1 "ON" ;
VAL_ 2578776064 OverallParams_ChargerEnable 0 "OFF" 1 "ON" ;
VAL_ 2578776064 OverallParams_HeaterEnable 0 "OFF" 1 "ON" ;
VAL_ 2578776064 OverallParams_BatteryContactor 0 "OFF" 1 "ON" ;
VAL_ 2578776064 OverallParams_BatteryFan 0 "OFF" 1 "ON" ;
VAL_ 2578776064 OverallParams_PowerReduction 0 "OFF" 1 "ON" ;
VAL_ 2578776064 OverallParams_DCDC_Control 0 "OFF" 1 "ON" ;
VAL_ 2578776064 OverallParams_ContactorPreCharge 0 "OFF" 1 "ON" ;
VAL_ 2578776064 OverallParams_ChargingStage 6 "CHARGE_STAGE_ERROR" 5 "CHARGE_STAGE_FINISHED" 4 "CHARGE_STAGE_BALANCE" 3 "CHARGE_STAGE_CHARGE" 2 "CHARGE_STAGE_PRECHARGE" 0 "CHARGE_STAGE_DISCONNECTED" 1 "CHARGE_STAGE_PREHEAT" ;
VAL_ 2578776064 OverallParams_LastChargingError 0 "NO ERROR" 1 "NO CELL COMMUNICATION" 2 "NO CELL COMMUNICATION 2" 3 "MAX CHARGING STAGE DURATION EXP" 4 "CELL COMMUNICATION LOST" 5 "CANT SET CELL MODULE BALANCING" 6 "CELL OR CELL MODULE TEMP TO HIGH" 7 "CELL COMMUNICATION LOST 2" 8 "NUMBER OF CELLS MISMATCH" 9 "CELL OVER VOLTAGE" 10 "CELL PROTECTION EVENT OCCURRED" ;
VAL_ 2578776064 OverallParams_ChargingInterlock 0 "OFF" 1 "ON" ;
VAL_ 2578777090 LoginLevel 0 "GUEST" 1 "USER" 2 "ADMIN" ;
VAL_ 2578777089 ContactorControl_ContactorState 0 "OPEN" 1 "CLOSE" ;
VAL_ 2578777092 Statistics_Identifier 63 "Voltage Reading Dev Prot Count" 62 "Bat Par Str Volt Dev Prot Count" 61 "Cell Wire Break Protection Count" 60 "Ext Temp Sensor Loss Prot Count" 59 "Cell Mod UnderHeat Prot Count" 58 "Pack Voltage Dev Prot Count" 57 "Cell Voltage Dev Prot Count" 56 "Cell Under Heat Prot Count" 55 "Pack Over Voltage Prot Count" 54 "Can Comm Watchdog Count" 53 "Pack Under Voltage Prot Count" 52 "Heater Relay Activation Count" 51 "No Current Sens Protection Count" 50 "None" 49 "Max Cell Temperature Difference" 48 "Max Cell Temperature" 47 "Min Cell Temperature" 46 "High Cell Temp Power Red Count" 45 "Cell Overheat Protection Count" 0 "Total Disharge" 1 "Total Charge" 2 "Total Discharge Energy" 3 "Total Charge Energy" 4 "Total Discharge Time" 5 "Total Charge Time" 6 "Total Distance" 7 "Master Clear Count" 8 "Max Discharge Current" 9 "Max Charge Current" 10 "Min Cell Voltage" 11 "Max Cell Voltage" 12 "Max Cell Voltage Difference" 13 "Min Pack Voltage" 14 "Max Pack Voltage" 15 "Min Cell Module Temperature" 16 "Max Cell Module Temperature" 17 "Max Cell Module Temperature Difference" 18 "BMS Starts Count" 19 "Under Voltage Protection Count" 20 "Over Voltage Protection Count" 21 "Discharge Over Current Protection Count" 22 "Charge Over Current Protection Count" 23 "Cell Module Over Heat Protection Count" 24 "Leakage Protection Count" 25 "No Cell Communication Protection Count" 26 "Low Voltage Power Reduction Count" 27 "High Current Power Reduction Count" 28 "High Cell Module Temp Power Reduction Count" 29 "Charger Connected Count" 30 "Charger Disconnected Count" 31 "Pre Heat Stage Count" 32 "Pre Charge Stage Count" 33 "Main Charge Stage Count" 34 "Balancing Stage Count" 35 "Charging Finished Count" 36 "Charging Error Count" 37 "Charging Retry Count" 38 "Trips Count" 39 "Charge Restarts Count" 40 "Configuration Error Count" 41 "Common CAN Error Count" 42 "Internal CAN Error Count" 43 "Configuration Mismatch Count" 44 "Common CAN Malfunction Count" ;
VAL_ 2578777092 Statistics_DataType 0 "Statistics Value" 1 "Additional Value" 2 "Statistics Timestamp" ;
VAL_ 2578777093 Events_Data_MSB 68 "Voltage Reading Dev Rec" 67 "Voltage Reading Dev Prot" 66 "Parallel String Volt Dev Rec" 65 "Parallel String Voltage Dev Prot" 64 "Cell Wire Break Protection Rec" 63 "Cell Wire Break Protection" 62 "Ext Temp Sensor Loss Prot Rec" 61 "Ext Temp Sensor Loss Protection" 60 "Cell Module UnherHeat Prot Rec" 59 "Cell Module UnderHeat Protection" 58 "Volt Diff Btw Srcs Recovered" 57 "Volt Diff Brw Srcs Crit Diff" 56 "Hi Par Bat Str Volt Diff Recover" 55 "Volt Diff Brw Par Bat Str Crt Hi" 54 "Cell Wire Break Recovered" 53 "Cell Wire Break Detected" 52 "Ext Temp Sens Loss Recovered" 51 "Ext Temp Sens Loss Detected" 50 "Crit Low Cell Module Temp Rec" 49 "Cell Module Temp Crit Low" 48 "Crit Hi Diff Btw Max N Min Vol R" 47 "Diff Btw Max N Min Volt Crit Hi" 46 "Crit Diff Btw Max N Min Cell V R" 45 "Diff Btw Max N Min Volt Cell  Hi" 44 "Crit Low Cell Temp Recovered" 43 "Cell Temperature Critically Low" 42 "Crit High Pack Voltage Recovered" 41 "Pack Voltage Critiaclly Low" 40 "CAN Comm Watchdog Time Out" 39 "Crit Low Pack Volt Recovered" 38 "Pack Voltage Critically Low" 37 "Detected Current Sensor" 36 "No Current Sensor Detected" 0 "No event" 1 "BMS Started" 2 "Lost Communication To Cells" 3 "Established Communication To Cells" 4 "Cells Voltage Critically Low" 5 "Critical Low Voltage Recovered" 6 "Cells Voltage Critically High " 7 "Critical High Voltage Recovered" 8 "Discharge Current Critically High" 9 "Discharge Critically High Current Recovered" 10 "Charge Current Critically High" 11 "Charge Critically High Current Recovered" 12 "Cell Module Temperature Critically High" 13 "Critical High Cell Module Temperature Recovered" 14 "Leakage Detected" 15 "Leakage Recovered" 16 "Warning: Low Voltage - Reducing Power" 17 "Power Reduction Due To Low Voltage Recovered" 18 "Warning: High Current - Reducing Power" 19 "Power Reduction Due To High Current Recovered" 20 "Warning: High Cell Module Temperature - Reducing Power" 21 "Power Reduction Due To High Cell Module Temperature Recovered" 22 "Charger Connected" 23 "Charger Disconnected" 24 "Started Pre-Heating Stage" 25 "Started Pre-Charging Stage" 26 "Started Main-Charging Stage" 27 "Started Balancing Stage" 28 "Charging Finished" 29 "Charging Error Occured" 30 "Retrying Charging" 31 "Restarting Charging" 32 "Cell Temperature Critically High" 33 "Critically High Cell Temperature Recovered" 34 "Warning: High Cell Temperature - Reducing Power" 35 "Power Reduction Due To High Cell Temperature Recovered" ;
VAL_ 2578777093 Events_DataType 0 "Event Info " 1 "Event timestamp" ;
VAL_ 256 OverallParams_LastChargingError 0 "NO ERROR" 1 "NO CELL COMMUNICATION" 2 "NO CELL COMMUNICATION 2" 3 "MAX CHARG STAGE DURATION EXPIRED" 4 "CELL COMMUNICATION LOST" 5 "CANT SET CELL MODULE BALANCING" 6 "CELL OR CELL MODULE TEMP TO HIGH" 7 "CELL COMMUNICATION LOST 2" 8 "NUMBER OF CELLS MISMATCH" 9 "CELL OVER VOLTAGE" 10 "CELL PROTECTION EVENT OCCURRED" ;
VAL_ 256 OverallParams_ChargingStage 6 "CHARGE_STAGE_ERROR" 5 "CHARGE_STAGE_FINISHED" 4 "CHARGE_STAGE_BALANCE" 3 "CHARGE_STAGE_CHARGE" 2 "CHARGE_STAGE_PRECHARGE" 0 "CHARGE_STAGE_DISCONNECTED" 1 "CHARGE_STAGE_PREHEAT" ;
VAL_ 256 OverallParams_ContactorPreCharge 0 "OFF" 1 "ON" ;
VAL_ 256 OverallParams_DCDC_Control 0 "OFF" 1 "ON" ;
VAL_ 256 OverallParams_ChargingInterlock 0 "OFF" 1 "ON" ;
VAL_ 256 OverallParams_PowerReduction 0 "OFF" 1 "ON" ;
VAL_ 256 OverallParams_BatteryFan 0 "OFF" 1 "ON" ;
VAL_ 256 OverallParams_BatteryContactor 0 "OFF" 1 "ON" ;
VAL_ 256 OverallParams_HeaterEnable 0 "OFF" 1 "ON" ;
VAL_ 256 OverallParams_ChargerEnable 0 "OFF" 1 "ON" ;
VAL_ 256 OverallParams_LeakageSensor 0 "OFF" 1 "ON" ;
VAL_ 256 OverallParams_FastCharge 0 "OFF" 1 "ON" ;
VAL_ 256 OverallParams_ChargerMains 0 "OFF" 1 "ON" ;
VAL_ 256 OverallParams_IgnitionKey 0 "OFF" 1 "ON" ;
VAL_ 553 ContactorControl_ContactorState 0 "OPEN" 1 "CLOSE" ;
VAL_ 563 Events_Data_MSB 68 "Voltage Reading Dev Rec" 67 "Voltage Reading Dev Prot" 66 "Parallel String Volt Dev Rec" 65 "Parallel String Voltage Dev Prot" 64 "Cell Wire Break Protection Rec" 63 "Cell Wire Break Protection" 62 "Ext Temp Sensor Loss Prot Rec" 61 "Ext Temp Sensor Loss Protection" 60 "Cell Module UnherHeat Prot Rec" 59 "Cell Module UnderHeat Protection" 58 "Volt Diff Btw Srcs Recovered" 57 "Volt Diff Brw Srcs Crit Diff" 56 "Hi Par Bat Str Volt Diff Recover" 55 "Volt Diff Brw Par Bat Str Crt Hi" 54 "Cell Wire Break Recovered" 53 "Cell Wire Break Detected" 52 "Ext Temp Sens Loss Recovered" 51 "Ext Temp Sens Loss Detected" 50 "Crit Low Cell Module Temp Rec" 49 "Cell Module Temp Crit Low" 48 "Crit Hi Diff Btw Max N Min Vol R" 47 "Diff Btw Max N Min Volt Crit Hi" 46 "Crit Diff Btw Max N Min Cell V R" 45 "Diff Btw Max N Min Volt Cell  Hi" 44 "Crit Low Cell Temp Recovered" 43 "Cell Temperature Critically Low" 42 "Crit High Pack Voltage Recovered" 41 "Pack Voltage Critiaclly Low" 40 "CAN Comm Watchdog Time Out" 39 "Crit Low Pack Volt Recovered" 38 "Pack Voltage Critically Low" 37 "Detected Current Sensor" 36 "No Current Sensor Detected" 0 "No event" 1 "BMS Started" 2 "Lost Communication To Cells" 3 "Established Communication To Cells" 4 "Cells Voltage Critically Low" 5 "Critical Low Voltage Recovered" 6 "Cells Voltage Critically High " 7 "Critical High Voltage Recovered" 8 "Discharge Current Critically High" 9 "Discharge Critically High Current Recovered" 10 "Charge Current Critically High" 11 "Charge Critically High Current Recovered" 12 "Cell Module Temperature Critically High" 13 "Critical High Cell Module Temperature Recovered" 14 "Leakage Detected" 15 "Leakage Recovered" 16 "Warning: Low Voltage - Reducing Power" 17 "Power Reduction Due To Low Voltage Recovered" 18 "Warning: High Current - Reducing Power" 19 "Power Reduction Due To High Current Recovered" 20 "Warning: High Cell Module Temperature - Reducing Power" 21 "Power Reduction Due To High Cell Module Temperature Recovered" 22 "Charger Connected" 23 "Charger Disconnected" 24 "Started Pre-Heating Stage" 25 "Started Pre-Charging Stage" 26 "Started Main-Charging Stage" 27 "Started Balancing Stage" 28 "Charging Finished" 29 "Charging Error Occured" 30 "Retrying Charging" 31 "Restarting Charging" 32 "Cell Temperature Critically High" 33 "Critically High Cell Temperature Recovered" 34 "Warning: High Cell Temperature - Reducing Power" 35 "Power Reduction Due To High Cell Temperature Recovered" ;
VAL_ 563 Events_DataType 0 "Event Info " 1 "Event timestamp" ;
VAL_ 567 LoginLevel 0 "GUEST" 1 "USER" 2 "ADMIN" ;
VAL_ 562 Statistics_Identifier 63 "Voltage Reading Dev Prot Count" 62 "Bat Par Str Volt Dev Prot Count" 61 "Cell Wire Break Protection Count" 60 "Ext Temp Sensor Loss Prot Count" 59 "Cell Mod UnderHeat Prot Count" 58 "Pack Voltage Dev Prot Count" 57 "Cell Voltage Dev Prot Count" 56 "Cell Under Heat Prot Count" 55 "Pack Over Voltage Prot Count" 54 "Can Comm Watchdog Count" 53 "Pack Under Voltage Prot Count" 52 "Heater Relay Activation Count" 51 "No Current Sens Protection Count" 50 "None" 49 "Max Cell Temperature Difference" 48 "Max Cell Temperature" 47 "Min Cell Temperature" 46 "High Cell Temp Power Red Count" 45 "Cell Overheat Protection Count" 0 "Total Disharge" 1 "Total Charge" 2 "Total Discharge Energy" 3 "Total Charge Energy" 4 "Total Discharge Time" 5 "Total Charge Time" 6 "Total Distance" 7 "Master Clear Count" 8 "Max Discharge Current" 9 "Max Charge Current" 10 "Min Cell Voltage" 11 "Max Cell Voltage" 12 "Max Cell Voltage Difference" 13 "Min Pack Voltage" 14 "Max Pack Voltage" 15 "Min Cell Module Temperature" 16 "Max Cell Module Temperature" 17 "Max Cell Module Temperature Difference" 18 "BMS Starts Count" 19 "Under Voltage Protection Count" 20 "Over Voltage Protection Count" 21 "Discharge Over Current Protection Count" 22 "Charge Over Current Protection Count" 23 "Cell Module Over Heat Protection Count" 24 "Leakage Protection Count" 25 "No Cell Communication Protection Count" 26 "Low Voltage Power Reduction Count" 27 "High Current Power Reduction Count" 28 "High Cell Module Temp Power Reduction Count" 29 "Charger Connected Count" 30 "Charger Disconnected Count" 31 "Pre Heat Stage Count" 32 "Pre Charge Stage Count" 33 "Main Charge Stage Count" 34 "Balancing Stage Count" 35 "Charging Finished Count" 36 "Charging Error Count" 37 "Charging Retry Count" 38 "Trips Count" 39 "Charge Restarts Count" 40 "Configuration Error Count" 41 "Common CAN Error Count" 42 "Internal CAN Error Count" 43 "Configuration Mismatch Count" 44 "Common CAN Malfunction Count" ;
VAL_ 562 Statistics_DataType 0 "Statistics Value" 1 "Additional Value" 2 "Statistics Timestamp" ;
VAL_ 1328 Neuro4_Discharge_Control 0 "DISABLED" 1 "ENABLED" ;
VAL_ 1328 Neuro4_Regeneration_Control 1 "ENABLED" 0 "DISABLED" ;
VAL_ 1328 Neuro4_CellTemperatureValid 1 "INVALID" 0 "VALID" ;
VAL_ 1328 Neuro4_ChargingStatus 0 "NOT CHARGING" 1 "CHARGING IN PROGRESS" 2 "CHARGING COMPLETE" 3 "CHARGING FAULT" ;
SIG_VALTYPE_ 1037 EnergyMeterEnergy : 1;
SIG_VALTYPE_ 269 EnergyMeterVoltage : 1;
SIG_VALTYPE_ 269 EnergyMeterCurrent : 1;
